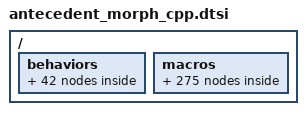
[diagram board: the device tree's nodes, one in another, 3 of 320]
// Cpp schema version v2.9
// Automatically generated by Antecedent Morph Configurator

/ {
    behaviors {
        // Mod-Morphs
        // Base layer
        // NE
        amcppneagm: amcppneagm {
            compatible = "zmk,behavior-mod-morph";
            #binding-cells = <0>;
            bindings = <&amcppnea>, <&amcppneg>;
            mods = <(MOD_LGUI)>;
        };
        amcppnecagm: amcppnecagm {
            compatible = "zmk,behavior-mod-morph";
            #binding-cells = <0>;
            bindings = <&amcppnec>, <&amcppneagm>;
            mods = <(MOD_LALT|MOD_LGUI)>;
        };
        amcppnem: amcppnem {
            compatible = "zmk,behavior-mod-morph";
            #binding-cells = <0>;
            bindings = <&amcppne>, <&amcppnecagm>;
            mods = <(MOD_LCTL|MOD_LALT|MOD_LGUI)>;
        };
        // E
        amcppeagm: amcppeagm {
            compatible = "zmk,behavior-mod-morph";
            #binding-cells = <0>;
            bindings = <&amcppea>, <&amcppeg>;
            mods = <(MOD_LGUI)>;
        };
        amcppecagm: amcppecagm {
            compatible = "zmk,behavior-mod-morph";
            #binding-cells = <0>;
            bindings = <&amcppec>, <&amcppeagm>;
            mods = <(MOD_LALT|MOD_LGUI)>;
        };
        amcppem: amcppem {
            compatible = "zmk,behavior-mod-morph";
            #binding-cells = <0>;
            bindings = <&amcppe>, <&amcppecagm>;
            mods = <(MOD_LCTL|MOD_LALT|MOD_LGUI)>;
        };
        // SE
        amcppseagm: amcppseagm {
            compatible = "zmk,behavior-mod-morph";
            #binding-cells = <0>;
            bindings = <&amcppsea>, <&amcppseg>;
            mods = <(MOD_LGUI)>;
        };
        amcppsecagm: amcppsecagm {
            compatible = "zmk,behavior-mod-morph";
            #binding-cells = <0>;
            bindings = <&amcppsec>, <&amcppseagm>;
            mods = <(MOD_LALT|MOD_LGUI)>;
        };
        amcppsem: amcppsem {
            compatible = "zmk,behavior-mod-morph";
            #binding-cells = <0>;
            bindings = <&amcppse>, <&amcppsecagm>;
            mods = <(MOD_LCTL|MOD_LALT|MOD_LGUI)>;
        };
        // NW
        amcppnwagm: amcppnwagm {
            compatible = "zmk,behavior-mod-morph";
            #binding-cells = <0>;
            bindings = <&amcppnwa>, <&amcppnwg>;
            mods = <(MOD_RGUI)>;
        };
        amcppnwcagm: amcppnwcagm {
            compatible = "zmk,behavior-mod-morph";
            #binding-cells = <0>;
            bindings = <&amcppnwc>, <&amcppnwagm>;
            mods = <(MOD_RALT|MOD_RGUI)>;
        };
        amcppnwm: amcppnwm {
            compatible = "zmk,behavior-mod-morph";
            #binding-cells = <0>;
            bindings = <&amcppnw>, <&amcppnwcagm>;
            mods = <(MOD_RCTL|MOD_RALT|MOD_RGUI)>;
        };
        // W
        amcppwagm: amcppwagm {
            compatible = "zmk,behavior-mod-morph";
            #binding-cells = <0>;
            bindings = <&amcppwa>, <&amcppwg>;
            mods = <(MOD_RGUI)>;
        };
        amcppwcagm: amcppwcagm {
            compatible = "zmk,behavior-mod-morph";
            #binding-cells = <0>;
            bindings = <&amcppwc>, <&amcppwagm>;
            mods = <(MOD_RALT|MOD_RGUI)>;
        };
        amcppwm: amcppwm {
            compatible = "zmk,behavior-mod-morph";
            #binding-cells = <0>;
            bindings = <&amcppw>, <&amcppwcagm>;
            mods = <(MOD_RCTL|MOD_RALT|MOD_RGUI)>;
        };
        // SW
        amcppswagm: amcppswagm {
            compatible = "zmk,behavior-mod-morph";
            #binding-cells = <0>;
            bindings = <&amcppswa>, <&amcppswg>;
            mods = <(MOD_RGUI)>;
        };
        amcppswcagm: amcppswcagm {
            compatible = "zmk,behavior-mod-morph";
            #binding-cells = <0>;
            bindings = <&amcppswc>, <&amcppswagm>;
            mods = <(MOD_RALT|MOD_RGUI)>;
        };
        amcppswm: amcppswm {
            compatible = "zmk,behavior-mod-morph";
            #binding-cells = <0>;
            bindings = <&amcppsw>, <&amcppswcagm>;
            mods = <(MOD_RCTL|MOD_RALT|MOD_RGUI)>;
        };
        // Antecedent Morphs
        amcppne: am_cpp_ne {
            compatible = "zmk,behavior-antecedent-morph";
            label = "AM_CPP_NE";
            #binding-cells = <0>;
            defaults = <&none>;
            bindings = <&amcpp_assert>, <&amcpp_break>, <&amcpp_case>, <&amcpp_default>, <&amcpp_enum>, <&amcpp_for>, <&amcpp_int_main>, <&amcpp_long_double>, <&amcpp_module>, <&amcpp_null>, <&amcpp_operator>, <&amcpp_private>, <&amcpp_qobject>, <&amcpp_return>, <&amcpp_struct>, <&amcpp_template>, <&amcpp_union>, <&amcpp_stdvector>, <&amcpp_while>, <&amcpp_extern>, <&amcpp_1024>, <&amcpp_4096>, <&amcpp_m3>, <&amcpp_m6>, <&amcpp_m10>, <&amcpp_void2>, <&amcpp_m16>, <&kp EQUAL>, <&amcpp_qt>, <&kp EQUAL>, <&kp EQUAL>, <&kp EQUAL>, <&kp EQUAL>, <&amcpp_error>, <&kp EQUAL>, <&kp EQUAL>, <&amcpp_m20>, <&amcpp_m25>, <&amcpp_m30>, <&kp EQUAL>;
            antecedents = <A B C D E F I L M N O P Q R S T U V W X N1 N4 SQT LBRC RBRC LPAR RPAR STAR COLON PRCNT CARET PLUS EXCL HASH PIPE AMPS LBKT RBKT EQUAL MINUS>;
            max-delay-ms = <U_ANTMORPH_DELAY>;
        };
        amcppnec: am_cpp_ne_c {
            compatible = "zmk,behavior-antecedent-morph";
            label = "AM_CPP_NE_C";
            #binding-cells = <0>;
            defaults = <&none>;
            bindings = <&amcpp_break1>, <&amcpp_default1>, <&amcpp_int_mainint_arg>, <&amcpp_long_double1>, <&amcpp_private1>, <&amcpp_qobjectcast>, <&amcpp_return1>, <&amcpp_typename>, <&amcpp_int_argc_char_a>, <&amcpp_this1>, <&amcpp_m26>, <&amcpp_m31>;
            antecedents = <B D I L P Q R T LPAR LBKT RBKT EQUAL>;
            max-delay-ms = <U_ANTMORPH_DELAY>;
        };
        amcppnea: am_cpp_ne_a {
            compatible = "zmk,behavior-antecedent-morph";
            label = "AM_CPP_NE_A";
            #binding-cells = <0>;
            defaults = <&none>;
            bindings = <&amcpp_qflag>, <&amcpp_int_mainvoid>, <&amcpp_long_double_con>, <&amcpp_qobject1>, <&amcpp_m21>, <&amcpp_m32>;
            antecedents = <E I L Q LBKT EQUAL>;
            max-delay-ms = <U_ANTMORPH_DELAY>;
        };
        amcppneg: am_cpp_ne_g {
            compatible = "zmk,behavior-antecedent-morph";
            label = "AM_CPP_NE_G";
            #binding-cells = <0>;
            defaults = <&none>;
            bindings = <&amcpp_qassert>, <&amcpp_qenum>, <&amcpp_private_slots>, <&amcpp_qgadget>;
            antecedents = <A E P Q>;
            max-delay-ms = <U_ANTMORPH_DELAY>;
        };
        amcppe: am_cpp_e {
            compatible = "zmk,behavior-antecedent-morph";
            label = "AM_CPP_E";
            #binding-cells = <0>;
            defaults = <&none>;
            bindings = <&amcpp_auto>, <&amcpp_bool>, <&amcpp_const>, <&amcpp_double>, <&amcpp_emit>, <&amcpp_float>, <&amcpp_goto>, <&amcpp_short>, <&amcpp_inline>, <&amcpp_long>, <&amcpp_stdmakeunique>, <&amcpp_nullptr>, <&amcpp_public>, <&amcpp_qstring>, <&amcpp_return2>, <&amcpp_static>, <&amcpp_this>, <&amcpp_using>, <&amcpp_void>, <&amcpp_qwidget>, <&amcpp_explicit>, <&amcpp_stdpair>, <&amcpp_stdtuple>, <&amcpp_stdcout>, <&amcpp_stdcin>, <&kp SEMI>, <&amcpp_m7>, <&kp SEMI>, <&amcpp_m13>, <&kp SEMI>, <&amcpp_void3>, <&amcpp_std>, <&amcpp_05>, <&amcpp_pragma>, <&amcpp_l11>, <&amcpp_m22>, <&kp SEMI>, <&amcpp_m28>, <&amcpp_01>, <&amcpp_rn>, <&kp GT>, <&amcpp_cpp_v29>;
            antecedents = <A B C D E F G H I L M N P Q R S T U V W X N2 N3 COMMA DOT SQT LBRC RBRC LPAR RPAR STAR COLON PLUS HASH UNDER LBKT RBKT SEMI EQUAL BSLH MINUS SPACE>;
            max-delay-ms = <U_ANTMORPH_DELAY>;
        };
        amcppec: am_cpp_e_c {
            compatible = "zmk,behavior-antecedent-morph";
            label = "AM_CPP_E_C";
            #binding-cells = <0>;
            defaults = <&none>;
            bindings = <&amcpp_auto_const>, <&amcpp_const1>, <&amcpp_double1>, <&amcpp_long1>, <&amcpp_public1>, <&amcpp_qstringview>, <&amcpp_staticcast>, <&amcpp_this_>, <&amcpp_void1>, <&amcpp_m4>, <&amcpp_m8>, <&amcpp_m11>, <&amcpp_m14>, <&amcpp_m17>, <&amcpp_void_const1>, <&amcpp_pragma_once>, <&amcpp_m23>, <&amcpp_m27>, <&amcpp_00>;
            antecedents = <A C D L P Q S T V SQT LBRC RBRC LPAR RPAR STAR HASH LBKT RBKT EQUAL>;
            max-delay-ms = <U_ANTMORPH_DELAY>;
        };
        amcppea: am_cpp_e_a {
            compatible = "zmk,behavior-antecedent-morph";
            label = "AM_CPP_E_A";
            #binding-cells = <0>;
            defaults = <&none>;
            bindings = <&amcpp_auto_const1>, <&amcpp_const2>, <&amcpp_double_const>, <&amcpp_long_const>, <&amcpp_qchar>, <&amcpp_void_const>, <&amcpp_l1>;
            antecedents = <A C D L Q V SQT>;
            max-delay-ms = <U_ANTMORPH_DELAY>;
        };
        amcppeg: am_cpp_e_g {
            compatible = "zmk,behavior-antecedent-morph";
            label = "AM_CPP_E_G";
            #binding-cells = <0>;
            defaults = <&none>;
            bindings = <&amcpp_auto1>, <&amcpp_constcast>, <&amcpp_public_slots>, <&amcpp_signals>, <&amcpp_ba>;
            antecedents = <A C P S SQT>;
            max-delay-ms = <U_ANTMORPH_DELAY>;
        };
        amcppse: am_cpp_se {
            compatible = "zmk,behavior-antecedent-morph";
            label = "AM_CPP_SE";
            #binding-cells = <0>;
            defaults = <&none>;
            bindings = <&amcpp_staticassert>, <&amcpp_begin>, <&amcpp_class>, <&amcpp_define>, <&amcpp_exit>, <&amcpp_final>, <&amcpp_import>, <&amcpp_mutable>, <&amcpp_0>, <&amcpp_protected>, <&amcpp_qvariant>, <&amcpp_register>, <&amcpp_signed>, <&amcpp_throw>, <&amcpp_unsigned>, <&amcpp_virtual>, <&amcpp_export>, <&amcpp_m>, <&amcpp_m5>, <&amcpp_m9>, <&amcpp_m12>, <&amcpp_m15>, <&amcpp_m18>, <&amcpp_char2>, <&amcpp_boost>, <&amcpp_warning>, <&amcpp_m24>, <&amcpp_m29>, <&amcpp_m33>, <&amcpp_rnrn>;
            antecedents = <A B C D E F I M N P Q R S T U V X COMMA SQT LBRC RBRC LPAR RPAR STAR COLON HASH LBKT SEMI EQUAL BSLH>;
            max-delay-ms = <U_ANTMORPH_DELAY>;
        };
        amcppsec: am_cpp_se_c {
            compatible = "zmk,behavior-antecedent-morph";
            label = "AM_CPP_SE_C";
            #binding-cells = <0>;
            defaults = <&none>;
            bindings = <&amcpp_cbegin>, <&amcpp_protected1>, <&amcpp_qvariantcast>, <&amcpp_try>, <&amcpp_m1>, <&amcpp_char_const1>, <&amcpp_deprecated>, <&amcpp_02>;
            antecedents = <B P Q T COMMA STAR LBKT EQUAL>;
            max-delay-ms = <U_ANTMORPH_DELAY>;
        };
        amcppsea: am_cpp_se_a {
            compatible = "zmk,behavior-antecedent-morph";
            label = "AM_CPP_SE_A";
            #binding-cells = <0>;
            defaults = <&none>;
            bindings = <&amcpp_rbegin>, <&amcpp_deprecated1>;
            antecedents = <B LBKT>;
            max-delay-ms = <U_ANTMORPH_DELAY>;
        };
        amcppseg: am_cpp_se_g {
            compatible = "zmk,behavior-antecedent-morph";
            label = "AM_CPP_SE_G";
            #binding-cells = <0>;
            defaults = <&none>;
            bindings = <&amcpp_crbegin>, <&amcpp_protected_slots>;
            antecedents = <B P>;
            max-delay-ms = <U_ANTMORPH_DELAY>;
        };
        amcppnw: am_cpp_nw {
            compatible = "zmk,behavior-antecedent-morph";
            label = "AM_CPP_NW";
            #binding-cells = <0>;
            defaults = <&none>;
            bindings = <&amcpp_asm>, <&amcpp_connect>, <&amcpp_delete>, <&amcpp_else_if>, <&amcpp_friend>, <&amcpp_char>, <&amcpp_int>, <&amcpp_stdmove>, <&amcpp_namespace>, <&amcpp_override>, <&amcpp_puts>, <&amcpp_qdebug>, <&amcpp_restrict>, <&amcpp_switch>, <&amcpp_typedef>, <&amcpp_stduniqueptr>, <&amcpp_volatile>, <&kp EQUAL>, <&kp EQUAL>, <&amcpp_include>, <&kp EQUAL>, <&amcpp_m19>, <&amcpp_embed>, <&amcpp_thread>, <&amcpp_expects>;
            antecedents = <A C D E F H I M N O P Q R S T U V COMMA DOT SQT FSLH RPAR HASH UNDER LBKT>;
            max-delay-ms = <U_ANTMORPH_DELAY>;
        };
        amcppnwc: am_cpp_nw_c {
            compatible = "zmk,behavior-antecedent-morph";
            label = "AM_CPP_NW_C";
            #binding-cells = <0>;
            defaults = <&none>;
            bindings = <&amcpp_asm_volatile__m>, <&amcpp_qobjectconnect>, <&amcpp_delete1>, <&amcpp_elif>, <&amcpp_char1>, <&amcpp_int1>, <&amcpp_namespace1>, <&amcpp_qcdebug>, <&amcpp_include_h>;
            antecedents = <A C D E H I N Q SQT>;
            max-delay-ms = <U_ANTMORPH_DELAY>;
        };
        amcppnwa: am_cpp_nw_a {
            compatible = "zmk,behavior-antecedent-morph";
            label = "AM_CPP_NW_A";
            #binding-cells = <0>;
            defaults = <&none>;
            bindings = <&amcpp_asm_volatilemfe>, <&amcpp_char_const>, <&amcpp_int_const>, <&amcpp_include_hpp>;
            antecedents = <A H I SQT>;
            max-delay-ms = <U_ANTMORPH_DELAY>;
        };
        amcppnwg: am_cpp_nw_g {
            compatible = "zmk,behavior-antecedent-morph";
            label = "AM_CPP_NW_G";
            #binding-cells = <0>;
            defaults = <&none>;
            bindings = <&none>;
            antecedents = <0x070100>;
            max-delay-ms = <U_ANTMORPH_DELAY>;
        };
        amcppw: am_cpp_w {
            compatible = "zmk,behavior-antecedent-morph";
            label = "AM_CPP_W";
            #binding-cells = <0>;
            defaults = <&none>;
            bindings = <&amcpp_stdasconst>, <&amcpp_continue>, <&amcpp_defined>, <&amcpp_else>, <&amcpp_free>, <&amcpp_catch>, <&amcpp_if>, <&amcpp_lse>, <&amcpp_malloc>, <&amcpp_false>, <&amcpp_stdoptional>, <&amcpp_printf>, <&amcpp_qsizetype>, <&amcpp_realloc>, <&amcpp_sizeof>, <&amcpp_sizet>, <&amcpp_using_namespace>, <&amcpp_vprintf>, <&amcpp_stdexchange>, <&amcpp_true>, <&amcpp_m2>, <&amcpp_endif>, <&amcpp_include1>, <&amcpp_ifdef>, <&amcpp_defined1>, <&amcpp_attribute>, <&amcpp_fallthrough>, <&amcpp_undef>;
            antecedents = <A C D E F H I L M N O P Q R S T U V X Y COMMA DOT SQT FSLH EXCL UNDER LBKT SPACE>;
            max-delay-ms = <U_ANTMORPH_DELAY>;
        };
        amcppwc: am_cpp_w_c {
            compatible = "zmk,behavior-antecedent-morph";
            label = "AM_CPP_W_C";
            #binding-cells = <0>;
            defaults = <&none>;
            bindings = <&amcpp_continue1>, <&amcpp_else1>, <&amcpp_catch1>, <&amcpp_if1>, <&amcpp_fprintf>, <&amcpp_sizeof1>, <&amcpp_ptrdifft>, <&amcpp_vfprintf>, <&amcpp_include_h1>, <&amcpp_ifndef>, <&amcpp_attribute_visib>, <&amcpp_likely>;
            antecedents = <C E H I P S T V SQT FSLH UNDER LBKT>;
            max-delay-ms = <U_ANTMORPH_DELAY>;
        };
        amcppwa: am_cpp_w_a {
            compatible = "zmk,behavior-antecedent-morph";
            label = "AM_CPP_W_A";
            #binding-cells = <0>;
            defaults = <&none>;
            bindings = <&amcpp_if_constexpr>, <&amcpp_sprintf>, <&amcpp_vsprintf>, <&amcpp_attribute_visib1>, <&amcpp_unlikely>;
            antecedents = <I P V UNDER LBKT>;
            max-delay-ms = <U_ANTMORPH_DELAY>;
        };
        amcppwg: am_cpp_w_g {
            compatible = "zmk,behavior-antecedent-morph";
            label = "AM_CPP_W_G";
            #binding-cells = <0>;
            defaults = <&none>;
            bindings = <&amcpp_snprintf>, <&amcpp_vsnprintf>, <&amcpp_attribute_secti>;
            antecedents = <P V UNDER>;
            max-delay-ms = <U_ANTMORPH_DELAY>;
        };
        amcppsw: am_cpp_sw {
            compatible = "zmk,behavior-antecedent-morph";
            label = "AM_CPP_SW";
            #binding-cells = <0>;
            defaults = <&none>;
            bindings = <&amcpp_alignas>, <&amcpp_constexpr>, <&amcpp_do>, <&amcpp_end>, <&amcpp_int64t>, <&amcpp_new>, <&amcpp_qbytearray>, <&amcpp_stdin>, <&amcpp_threadlocal>, <&amcpp_uint64t>, <&amcpp_elifdef>, <&amcpp_declspec>, <&amcpp_maybeunused>;
            antecedents = <A C D E I N Q S T U FSLH UNDER LBKT>;
            max-delay-ms = <U_ANTMORPH_DELAY>;
        };
        amcppswc: am_cpp_sw_c {
            compatible = "zmk,behavior-antecedent-morph";
            label = "AM_CPP_SW_C";
            #binding-cells = <0>;
            defaults = <&none>;
            bindings = <&amcpp_alignof>, <&amcpp_cend>, <&amcpp_int32t>, <&amcpp_stdout>, <&amcpp_uint32t>, <&amcpp_elifndef>, <&amcpp_nodiscard>;
            antecedents = <A E I S U FSLH LBKT>;
            max-delay-ms = <U_ANTMORPH_DELAY>;
        };
        amcppswa: am_cpp_sw_a {
            compatible = "zmk,behavior-antecedent-morph";
            label = "AM_CPP_SW_A";
            #binding-cells = <0>;
            defaults = <&none>;
            bindings = <&amcpp_rend>, <&amcpp_int16t>, <&amcpp_stderr>, <&amcpp_uint16t>, <&amcpp_nodiscard1>;
            antecedents = <E I S U LBKT>;
            max-delay-ms = <U_ANTMORPH_DELAY>;
        };
        amcppswg: am_cpp_sw_g {
            compatible = "zmk,behavior-antecedent-morph";
            label = "AM_CPP_SW_G";
            #binding-cells = <0>;
            defaults = <&none>;
            bindings = <&amcpp_crend>, <&amcpp_int8t>, <&amcpp_uint8t>;
            antecedents = <E I U>;
            max-delay-ms = <U_ANTMORPH_DELAY>;
        };
    };
    macros {
        // 'A'
        amcpp_assert: amcpp_assert {
            compatible = "zmk,behavior-macro";
            #binding-cells = <0>;
            wait-ms = <U_ANTMORPH_MACRO_WAIT>;
            tap-ms = <U_ANTMORPH_MACRO_TAP>;
            // (a)ssert(
            bindings = <&macro_tap &kp S &kp S &kp E &kp R &kp T &kp LPAR>;
        };
        amcpp_qassert: amcpp_qassert {
            compatible = "zmk,behavior-macro";
            #binding-cells = <0>;
            wait-ms = <U_ANTMORPH_MACRO_WAIT>;
            tap-ms = <U_ANTMORPH_MACRO_TAP>;
            // [a]Q_ASSERT(
            bindings = <&macro_release &kp LGUI>, <&macro_tap &kp LGUI>, <&macro_tap &kp BSPC &kp LS(Q) &kp UNDER &kp LS(A) &kp LS(S) &kp LS(S) &kp LS(E) &kp LS(R) &kp LS(T) &kp LPAR>;
        };
        amcpp_auto: amcpp_auto {
            compatible = "zmk,behavior-macro";
            #binding-cells = <0>;
            wait-ms = <U_ANTMORPH_MACRO_WAIT>;
            tap-ms = <U_ANTMORPH_MACRO_TAP>;
            // (a)uto
            bindings = <&macro_tap &kp U &kp T &kp O>;
        };
        amcpp_auto_const: amcpp_auto_const {
            compatible = "zmk,behavior-macro";
            #binding-cells = <0>;
            wait-ms = <U_ANTMORPH_MACRO_WAIT>;
            tap-ms = <U_ANTMORPH_MACRO_TAP>;
            // (a)uto const &
            bindings = <&macro_release &kp LCTRL>, <&macro_tap &kp U &kp T &kp O &kp SPACE &kp C &kp O &kp N &kp S &kp T &kp SPACE &kp AMPS>;
        };
        amcpp_auto_const1: amcpp_auto_const1 {
            compatible = "zmk,behavior-macro";
            #binding-cells = <0>;
            wait-ms = <U_ANTMORPH_MACRO_WAIT>;
            tap-ms = <U_ANTMORPH_MACRO_TAP>;
            // (a)uto const
            bindings = <&macro_release &kp LALT>, <&macro_tap &kp LALT>, <&macro_tap &kp U &kp T &kp O &kp SPACE &kp C &kp O &kp N &kp S &kp T>;
        };
        amcpp_auto1: amcpp_auto1 {
            compatible = "zmk,behavior-macro";
            #binding-cells = <0>;
            wait-ms = <U_ANTMORPH_MACRO_WAIT>;
            tap-ms = <U_ANTMORPH_MACRO_TAP>;
            // (a)uto *
            bindings = <&macro_release &kp LGUI>, <&macro_tap &kp LGUI>, <&macro_tap &kp U &kp T &kp O &kp SPACE &kp STAR>;
        };
        amcpp_staticassert: amcpp_staticassert {
            compatible = "zmk,behavior-macro";
            #binding-cells = <0>;
            wait-ms = <U_ANTMORPH_MACRO_WAIT>;
            tap-ms = <U_ANTMORPH_MACRO_TAP>;
            // [a]static_assert(
            bindings = <&macro_tap &kp BSPC &kp S &kp T &kp A &kp T &kp I &kp C &kp UNDER &kp A &kp S &kp S &kp E &kp R &kp T &kp LPAR>;
        };
        amcpp_asm: amcpp_asm {
            compatible = "zmk,behavior-macro";
            #binding-cells = <0>;
            wait-ms = <U_ANTMORPH_MACRO_WAIT>;
            tap-ms = <U_ANTMORPH_MACRO_TAP>;
            // (a)sm ("
            bindings = <&macro_tap &kp S &kp M &kp SPACE &kp LPAR &kp DQT>;
        };
        amcpp_asm_volatile__m: amcpp_asm_volatile__m {
            compatible = "zmk,behavior-macro";
            #binding-cells = <0>;
            wait-ms = <U_ANTMORPH_MACRO_WAIT>;
            tap-ms = <U_ANTMORPH_MACRO_TAP>;
            // (a)sm volatile(""  ::: "memory")
            bindings = <&macro_release &kp RCTRL>, <&macro_tap &kp S &kp M &kp SPACE &kp V &kp O &kp L &kp A &kp T &kp I &kp L &kp E &kp LPAR &kp DQT &kp DQT &kp SPACE &kp SPACE &kp COLON &kp COLON &kp COLON &kp SPACE &kp DQT &kp M &kp E &kp M &kp O &kp R &kp Y &kp DQT &kp RPAR>;
        };
        amcpp_asm_volatilemfe: amcpp_asm_volatilemfe {
            compatible = "zmk,behavior-macro";
            #binding-cells = <0>;
            wait-ms = <U_ANTMORPH_MACRO_WAIT>;
            tap-ms = <U_ANTMORPH_MACRO_TAP>;
            // (a)sm volatile("mfence" :: "memory")
            bindings = <&macro_release &kp RALT>, <&macro_tap &kp RALT>, <&macro_tap &kp S &kp M &kp SPACE &kp V &kp O &kp L &kp A &kp T &kp I &kp L &kp E &kp LPAR &kp DQT &kp M &kp F &kp E &kp N &kp C &kp E &kp DQT &kp SPACE &kp COLON &kp COLON &kp SPACE &kp DQT &kp M &kp E &kp M &kp O &kp R &kp Y &kp DQT &kp RPAR>;
        };
        amcpp_stdasconst: amcpp_stdasconst {
            compatible = "zmk,behavior-macro";
            #binding-cells = <0>;
            wait-ms = <U_ANTMORPH_MACRO_WAIT>;
            tap-ms = <U_ANTMORPH_MACRO_TAP>;
            // [a]std::as_const(
            bindings = <&macro_tap &kp BSPC &kp S &kp T &kp D &kp COLON &kp COLON &kp A &kp S &kp UNDER &kp C &kp O &kp N &kp S &kp T &kp LPAR>;
        };
        amcpp_alignas: amcpp_alignas {
            compatible = "zmk,behavior-macro";
            #binding-cells = <0>;
            wait-ms = <U_ANTMORPH_MACRO_WAIT>;
            tap-ms = <U_ANTMORPH_MACRO_TAP>;
            // (a)lignas(
            bindings = <&macro_tap &kp L &kp I &kp G &kp N &kp A &kp S &kp LPAR>;
        };
        amcpp_alignof: amcpp_alignof {
            compatible = "zmk,behavior-macro";
            #binding-cells = <0>;
            wait-ms = <U_ANTMORPH_MACRO_WAIT>;
            tap-ms = <U_ANTMORPH_MACRO_TAP>;
            // (a)lignof(
            bindings = <&macro_release &kp RCTRL>, <&macro_tap &kp L &kp I &kp G &kp N &kp O &kp F &kp LPAR>;
        };
        // 'B'
        amcpp_break: amcpp_break {
            compatible = "zmk,behavior-macro";
            #binding-cells = <0>;
            wait-ms = <U_ANTMORPH_MACRO_WAIT>;
            tap-ms = <U_ANTMORPH_MACRO_TAP>;
            // (b)reak;
            bindings = <&macro_tap &kp R &kp E &kp A &kp K &kp SEMI>;
        };
        amcpp_break1: amcpp_break1 {
            compatible = "zmk,behavior-macro";
            #binding-cells = <0>;
            wait-ms = <U_ANTMORPH_MACRO_WAIT>;
            tap-ms = <U_ANTMORPH_MACRO_TAP>;
            // (b)reak;⏎
            bindings = <&macro_release &kp LCTRL>, <&macro_tap &kp R &kp E &kp A &kp K &kp SEMI &kp RET>;
        };
        amcpp_bool: amcpp_bool {
            compatible = "zmk,behavior-macro";
            #binding-cells = <0>;
            wait-ms = <U_ANTMORPH_MACRO_WAIT>;
            tap-ms = <U_ANTMORPH_MACRO_TAP>;
            // (b)ool
            bindings = <&macro_tap &kp O &kp O &kp L>;
        };
        amcpp_begin: amcpp_begin {
            compatible = "zmk,behavior-macro";
            #binding-cells = <0>;
            wait-ms = <U_ANTMORPH_MACRO_WAIT>;
            tap-ms = <U_ANTMORPH_MACRO_TAP>;
            // (b)egin()
            bindings = <&macro_tap &kp E &kp G &kp I &kp N &kp LPAR &kp RPAR>;
        };
        amcpp_cbegin: amcpp_cbegin {
            compatible = "zmk,behavior-macro";
            #binding-cells = <0>;
            wait-ms = <U_ANTMORPH_MACRO_WAIT>;
            tap-ms = <U_ANTMORPH_MACRO_TAP>;
            // [b]cbegin()
            bindings = <&macro_release &kp LCTRL>, <&macro_tap &kp BSPC &kp C &kp B &kp E &kp G &kp I &kp N &kp LPAR &kp RPAR>;
        };
        amcpp_rbegin: amcpp_rbegin {
            compatible = "zmk,behavior-macro";
            #binding-cells = <0>;
            wait-ms = <U_ANTMORPH_MACRO_WAIT>;
            tap-ms = <U_ANTMORPH_MACRO_TAP>;
            // [b]rbegin()
            bindings = <&macro_release &kp LALT>, <&macro_tap &kp LALT>, <&macro_tap &kp BSPC &kp R &kp B &kp E &kp G &kp I &kp N &kp LPAR &kp RPAR>;
        };
        amcpp_crbegin: amcpp_crbegin {
            compatible = "zmk,behavior-macro";
            #binding-cells = <0>;
            wait-ms = <U_ANTMORPH_MACRO_WAIT>;
            tap-ms = <U_ANTMORPH_MACRO_TAP>;
            // [b]crbegin()
            bindings = <&macro_release &kp LGUI>, <&macro_tap &kp LGUI>, <&macro_tap &kp BSPC &kp C &kp R &kp B &kp E &kp G &kp I &kp N &kp LPAR &kp RPAR>;
        };
        // 'C'
        amcpp_case: amcpp_case {
            compatible = "zmk,behavior-macro";
            #binding-cells = <0>;
            wait-ms = <U_ANTMORPH_MACRO_WAIT>;
            tap-ms = <U_ANTMORPH_MACRO_TAP>;
            // (c)ase 
            bindings = <&macro_tap &kp A &kp S &kp E &kp SPACE>;
        };
        amcpp_const: amcpp_const {
            compatible = "zmk,behavior-macro";
            #binding-cells = <0>;
            wait-ms = <U_ANTMORPH_MACRO_WAIT>;
            tap-ms = <U_ANTMORPH_MACRO_TAP>;
            // (c)onst
            bindings = <&macro_tap &kp O &kp N &kp S &kp T>;
        };
        amcpp_const1: amcpp_const1 {
            compatible = "zmk,behavior-macro";
            #binding-cells = <0>;
            wait-ms = <U_ANTMORPH_MACRO_WAIT>;
            tap-ms = <U_ANTMORPH_MACRO_TAP>;
            // (c)onst *
            bindings = <&macro_release &kp LCTRL>, <&macro_tap &kp O &kp N &kp S &kp T &kp SPACE &kp STAR>;
        };
        amcpp_const2: amcpp_const2 {
            compatible = "zmk,behavior-macro";
            #binding-cells = <0>;
            wait-ms = <U_ANTMORPH_MACRO_WAIT>;
            tap-ms = <U_ANTMORPH_MACRO_TAP>;
            // (c)onst &
            bindings = <&macro_release &kp LALT>, <&macro_tap &kp LALT>, <&macro_tap &kp O &kp N &kp S &kp T &kp SPACE &kp AMPS>;
        };
        amcpp_constcast: amcpp_constcast {
            compatible = "zmk,behavior-macro";
            #binding-cells = <0>;
            wait-ms = <U_ANTMORPH_MACRO_WAIT>;
            tap-ms = <U_ANTMORPH_MACRO_TAP>;
            // (c)onst_cast<
            bindings = <&macro_release &kp LGUI>, <&macro_tap &kp LGUI>, <&macro_tap &kp O &kp N &kp S &kp T &kp UNDER &kp C &kp A &kp S &kp T &kp LT>;
        };
        amcpp_class: amcpp_class {
            compatible = "zmk,behavior-macro";
            #binding-cells = <0>;
            wait-ms = <U_ANTMORPH_MACRO_WAIT>;
            tap-ms = <U_ANTMORPH_MACRO_TAP>;
            // (c)lass 
            bindings = <&macro_tap &kp L &kp A &kp S &kp S &kp SPACE>;
        };
        amcpp_connect: amcpp_connect {
            compatible = "zmk,behavior-macro";
            #binding-cells = <0>;
            wait-ms = <U_ANTMORPH_MACRO_WAIT>;
            tap-ms = <U_ANTMORPH_MACRO_TAP>;
            // (c)onnect(
            bindings = <&macro_tap &kp O &kp N &kp N &kp E &kp C &kp T &kp LPAR>;
        };
        amcpp_qobjectconnect: amcpp_qobjectconnect {
            compatible = "zmk,behavior-macro";
            #binding-cells = <0>;
            wait-ms = <U_ANTMORPH_MACRO_WAIT>;
            tap-ms = <U_ANTMORPH_MACRO_TAP>;
            // [c]QObject::connect(
            bindings = <&macro_release &kp RCTRL>, <&macro_tap &kp BSPC &kp LS(Q) &kp LS(O) &kp B &kp J &kp E &kp C &kp T &kp COLON &kp COLON &kp C &kp O &kp N &kp N &kp E &kp C &kp T &kp LPAR>;
        };
        amcpp_continue: amcpp_continue {
            compatible = "zmk,behavior-macro";
            #binding-cells = <0>;
            wait-ms = <U_ANTMORPH_MACRO_WAIT>;
            tap-ms = <U_ANTMORPH_MACRO_TAP>;
            // (c)ontinue;
            bindings = <&macro_tap &kp O &kp N &kp T &kp I &kp N &kp U &kp E &kp SEMI>;
        };
        amcpp_continue1: amcpp_continue1 {
            compatible = "zmk,behavior-macro";
            #binding-cells = <0>;
            wait-ms = <U_ANTMORPH_MACRO_WAIT>;
            tap-ms = <U_ANTMORPH_MACRO_TAP>;
            // (c)ontinue;⏎
            bindings = <&macro_release &kp RCTRL>, <&macro_tap &kp O &kp N &kp T &kp I &kp N &kp U &kp E &kp SEMI &kp RET>;
        };
        amcpp_constexpr: amcpp_constexpr {
            compatible = "zmk,behavior-macro";
            #binding-cells = <0>;
            wait-ms = <U_ANTMORPH_MACRO_WAIT>;
            tap-ms = <U_ANTMORPH_MACRO_TAP>;
            // (c)onstexpr
            bindings = <&macro_tap &kp O &kp N &kp S &kp T &kp E &kp X &kp P &kp R>;
        };
        // 'D'
        amcpp_default: amcpp_default {
            compatible = "zmk,behavior-macro";
            #binding-cells = <0>;
            wait-ms = <U_ANTMORPH_MACRO_WAIT>;
            tap-ms = <U_ANTMORPH_MACRO_TAP>;
            // (d)efault
            bindings = <&macro_tap &kp E &kp F &kp A &kp U &kp L &kp T>;
        };
        amcpp_default1: amcpp_default1 {
            compatible = "zmk,behavior-macro";
            #binding-cells = <0>;
            wait-ms = <U_ANTMORPH_MACRO_WAIT>;
            tap-ms = <U_ANTMORPH_MACRO_TAP>;
            // (d)efault:⏎
            bindings = <&macro_release &kp LCTRL>, <&macro_tap &kp E &kp F &kp A &kp U &kp L &kp T &kp COLON &kp RET>;
        };
        amcpp_double: amcpp_double {
            compatible = "zmk,behavior-macro";
            #binding-cells = <0>;
            wait-ms = <U_ANTMORPH_MACRO_WAIT>;
            tap-ms = <U_ANTMORPH_MACRO_TAP>;
            // (d)ouble
            bindings = <&macro_tap &kp O &kp U &kp B &kp L &kp E>;
        };
        amcpp_double1: amcpp_double1 {
            compatible = "zmk,behavior-macro";
            #binding-cells = <0>;
            wait-ms = <U_ANTMORPH_MACRO_WAIT>;
            tap-ms = <U_ANTMORPH_MACRO_TAP>;
            // (d)ouble *
            bindings = <&macro_release &kp LCTRL>, <&macro_tap &kp O &kp U &kp B &kp L &kp E &kp SPACE &kp STAR>;
        };
        amcpp_double_const: amcpp_double_const {
            compatible = "zmk,behavior-macro";
            #binding-cells = <0>;
            wait-ms = <U_ANTMORPH_MACRO_WAIT>;
            tap-ms = <U_ANTMORPH_MACRO_TAP>;
            // (d)ouble const *
            bindings = <&macro_release &kp LALT>, <&macro_tap &kp LALT>, <&macro_tap &kp O &kp U &kp B &kp L &kp E &kp SPACE &kp C &kp O &kp N &kp S &kp T &kp SPACE &kp STAR>;
        };
        amcpp_define: amcpp_define {
            compatible = "zmk,behavior-macro";
            #binding-cells = <0>;
            wait-ms = <U_ANTMORPH_MACRO_WAIT>;
            tap-ms = <U_ANTMORPH_MACRO_TAP>;
            // [d]#define 
            bindings = <&macro_tap &kp BSPC &kp HASH &kp D &kp E &kp F &kp I &kp N &kp E &kp SPACE>;
        };
        amcpp_delete: amcpp_delete {
            compatible = "zmk,behavior-macro";
            #binding-cells = <0>;
            wait-ms = <U_ANTMORPH_MACRO_WAIT>;
            tap-ms = <U_ANTMORPH_MACRO_TAP>;
            // (d)elete
            bindings = <&macro_tap &kp E &kp L &kp E &kp T &kp E>;
        };
        amcpp_delete1: amcpp_delete1 {
            compatible = "zmk,behavior-macro";
            #binding-cells = <0>;
            wait-ms = <U_ANTMORPH_MACRO_WAIT>;
            tap-ms = <U_ANTMORPH_MACRO_TAP>;
            // (d)elete[] 
            bindings = <&macro_release &kp RCTRL>, <&macro_tap &kp E &kp L &kp E &kp T &kp E &kp LBKT &kp RBKT &kp SPACE>;
        };
        amcpp_defined: amcpp_defined {
            compatible = "zmk,behavior-macro";
            #binding-cells = <0>;
            wait-ms = <U_ANTMORPH_MACRO_WAIT>;
            tap-ms = <U_ANTMORPH_MACRO_TAP>;
            // (d)efined(
            bindings = <&macro_tap &kp E &kp F &kp I &kp N &kp E &kp D &kp LPAR>;
        };
        amcpp_do: amcpp_do {
            compatible = "zmk,behavior-macro";
            #binding-cells = <0>;
            wait-ms = <U_ANTMORPH_MACRO_WAIT>;
            tap-ms = <U_ANTMORPH_MACRO_TAP>;
            // (d)o {⏎
            bindings = <&macro_tap &kp O &kp SPACE &kp LBRC &kp RET>;
        };
        // 'E'
        amcpp_enum: amcpp_enum {
            compatible = "zmk,behavior-macro";
            #binding-cells = <0>;
            wait-ms = <U_ANTMORPH_MACRO_WAIT>;
            tap-ms = <U_ANTMORPH_MACRO_TAP>;
            // (e)num 
            bindings = <&macro_tap &kp N &kp U &kp M &kp SPACE>;
        };
        amcpp_qflag: amcpp_qflag {
            compatible = "zmk,behavior-macro";
            #binding-cells = <0>;
            wait-ms = <U_ANTMORPH_MACRO_WAIT>;
            tap-ms = <U_ANTMORPH_MACRO_TAP>;
            // [e]Q_FLAG(
            bindings = <&macro_release &kp LALT>, <&macro_tap &kp LALT>, <&macro_tap &kp BSPC &kp LS(Q) &kp UNDER &kp LS(F) &kp LS(L) &kp LS(A) &kp LS(G) &kp LPAR>;
        };
        amcpp_qenum: amcpp_qenum {
            compatible = "zmk,behavior-macro";
            #binding-cells = <0>;
            wait-ms = <U_ANTMORPH_MACRO_WAIT>;
            tap-ms = <U_ANTMORPH_MACRO_TAP>;
            // [e]Q_ENUM(
            bindings = <&macro_release &kp LGUI>, <&macro_tap &kp LGUI>, <&macro_tap &kp BSPC &kp LS(Q) &kp UNDER &kp LS(E) &kp LS(N) &kp LS(U) &kp LS(M) &kp LPAR>;
        };
        amcpp_emit: amcpp_emit {
            compatible = "zmk,behavior-macro";
            #binding-cells = <0>;
            wait-ms = <U_ANTMORPH_MACRO_WAIT>;
            tap-ms = <U_ANTMORPH_MACRO_TAP>;
            // (e)mit 
            bindings = <&macro_tap &kp M &kp I &kp T &kp SPACE>;
        };
        amcpp_exit: amcpp_exit {
            compatible = "zmk,behavior-macro";
            #binding-cells = <0>;
            wait-ms = <U_ANTMORPH_MACRO_WAIT>;
            tap-ms = <U_ANTMORPH_MACRO_TAP>;
            // (e)xit(
            bindings = <&macro_tap &kp X &kp I &kp T &kp LPAR>;
        };
        amcpp_else_if: amcpp_else_if {
            compatible = "zmk,behavior-macro";
            #binding-cells = <0>;
            wait-ms = <U_ANTMORPH_MACRO_WAIT>;
            tap-ms = <U_ANTMORPH_MACRO_TAP>;
            // (e)lse if (
            bindings = <&macro_tap &kp L &kp S &kp E &kp SPACE &kp I &kp F &kp SPACE &kp LPAR>;
        };
        amcpp_elif: amcpp_elif {
            compatible = "zmk,behavior-macro";
            #binding-cells = <0>;
            wait-ms = <U_ANTMORPH_MACRO_WAIT>;
            tap-ms = <U_ANTMORPH_MACRO_TAP>;
            // [e]#elif 
            bindings = <&macro_release &kp RCTRL>, <&macro_tap &kp BSPC &kp HASH &kp E &kp L &kp I &kp F &kp SPACE>;
        };
        amcpp_else: amcpp_else {
            compatible = "zmk,behavior-macro";
            #binding-cells = <0>;
            wait-ms = <U_ANTMORPH_MACRO_WAIT>;
            tap-ms = <U_ANTMORPH_MACRO_TAP>;
            // (e)lse
            bindings = <&macro_tap &kp L &kp S &kp E>;
        };
        amcpp_else1: amcpp_else1 {
            compatible = "zmk,behavior-macro";
            #binding-cells = <0>;
            wait-ms = <U_ANTMORPH_MACRO_WAIT>;
            tap-ms = <U_ANTMORPH_MACRO_TAP>;
            // [e]#else
            bindings = <&macro_release &kp RCTRL>, <&macro_tap &kp BSPC &kp HASH &kp E &kp L &kp S &kp E>;
        };
        amcpp_end: amcpp_end {
            compatible = "zmk,behavior-macro";
            #binding-cells = <0>;
            wait-ms = <U_ANTMORPH_MACRO_WAIT>;
            tap-ms = <U_ANTMORPH_MACRO_TAP>;
            // (e)nd()
            bindings = <&macro_tap &kp N &kp D &kp LPAR &kp RPAR>;
        };
        amcpp_cend: amcpp_cend {
            compatible = "zmk,behavior-macro";
            #binding-cells = <0>;
            wait-ms = <U_ANTMORPH_MACRO_WAIT>;
            tap-ms = <U_ANTMORPH_MACRO_TAP>;
            // [e]cend()
            bindings = <&macro_release &kp RCTRL>, <&macro_tap &kp BSPC &kp C &kp E &kp N &kp D &kp LPAR &kp RPAR>;
        };
        amcpp_rend: amcpp_rend {
            compatible = "zmk,behavior-macro";
            #binding-cells = <0>;
            wait-ms = <U_ANTMORPH_MACRO_WAIT>;
            tap-ms = <U_ANTMORPH_MACRO_TAP>;
            // [e]rend()
            bindings = <&macro_release &kp RALT>, <&macro_tap &kp RALT>, <&macro_tap &kp BSPC &kp R &kp E &kp N &kp D &kp LPAR &kp RPAR>;
        };
        amcpp_crend: amcpp_crend {
            compatible = "zmk,behavior-macro";
            #binding-cells = <0>;
            wait-ms = <U_ANTMORPH_MACRO_WAIT>;
            tap-ms = <U_ANTMORPH_MACRO_TAP>;
            // [e]crend()
            bindings = <&macro_release &kp RGUI>, <&macro_tap &kp RGUI>, <&macro_tap &kp BSPC &kp C &kp R &kp E &kp N &kp D &kp LPAR &kp RPAR>;
        };
        // 'F'
        amcpp_for: amcpp_for {
            compatible = "zmk,behavior-macro";
            #binding-cells = <0>;
            wait-ms = <U_ANTMORPH_MACRO_WAIT>;
            tap-ms = <U_ANTMORPH_MACRO_TAP>;
            // (f)or (
            bindings = <&macro_tap &kp O &kp R &kp SPACE &kp LPAR>;
        };
        amcpp_float: amcpp_float {
            compatible = "zmk,behavior-macro";
            #binding-cells = <0>;
            wait-ms = <U_ANTMORPH_MACRO_WAIT>;
            tap-ms = <U_ANTMORPH_MACRO_TAP>;
            // (f)loat
            bindings = <&macro_tap &kp L &kp O &kp A &kp T>;
        };
        amcpp_final: amcpp_final {
            compatible = "zmk,behavior-macro";
            #binding-cells = <0>;
            wait-ms = <U_ANTMORPH_MACRO_WAIT>;
            tap-ms = <U_ANTMORPH_MACRO_TAP>;
            // (f)inal
            bindings = <&macro_tap &kp I &kp N &kp A &kp L>;
        };
        amcpp_friend: amcpp_friend {
            compatible = "zmk,behavior-macro";
            #binding-cells = <0>;
            wait-ms = <U_ANTMORPH_MACRO_WAIT>;
            tap-ms = <U_ANTMORPH_MACRO_TAP>;
            // (f)riend 
            bindings = <&macro_tap &kp R &kp I &kp E &kp N &kp D &kp SPACE>;
        };
        amcpp_free: amcpp_free {
            compatible = "zmk,behavior-macro";
            #binding-cells = <0>;
            wait-ms = <U_ANTMORPH_MACRO_WAIT>;
            tap-ms = <U_ANTMORPH_MACRO_TAP>;
            // (f)ree(
            bindings = <&macro_tap &kp R &kp E &kp E &kp LPAR>;
        };
        // 'G'
        amcpp_goto: amcpp_goto {
            compatible = "zmk,behavior-macro";
            #binding-cells = <0>;
            wait-ms = <U_ANTMORPH_MACRO_WAIT>;
            tap-ms = <U_ANTMORPH_MACRO_TAP>;
            // (g)oto 
            bindings = <&macro_tap &kp O &kp T &kp O &kp SPACE>;
        };
        // 'H'
        amcpp_short: amcpp_short {
            compatible = "zmk,behavior-macro";
            #binding-cells = <0>;
            wait-ms = <U_ANTMORPH_MACRO_WAIT>;
            tap-ms = <U_ANTMORPH_MACRO_TAP>;
            // [h]short
            bindings = <&macro_tap &kp BSPC &kp S &kp H &kp O &kp R &kp T>;
        };
        amcpp_char: amcpp_char {
            compatible = "zmk,behavior-macro";
            #binding-cells = <0>;
            wait-ms = <U_ANTMORPH_MACRO_WAIT>;
            tap-ms = <U_ANTMORPH_MACRO_TAP>;
            // [h]char
            bindings = <&macro_tap &kp BSPC &kp C &kp H &kp A &kp R>;
        };
        amcpp_char1: amcpp_char1 {
            compatible = "zmk,behavior-macro";
            #binding-cells = <0>;
            wait-ms = <U_ANTMORPH_MACRO_WAIT>;
            tap-ms = <U_ANTMORPH_MACRO_TAP>;
            // [h]char *
            bindings = <&macro_release &kp RCTRL>, <&macro_tap &kp BSPC &kp C &kp H &kp A &kp R &kp SPACE &kp STAR>;
        };
        amcpp_char_const: amcpp_char_const {
            compatible = "zmk,behavior-macro";
            #binding-cells = <0>;
            wait-ms = <U_ANTMORPH_MACRO_WAIT>;
            tap-ms = <U_ANTMORPH_MACRO_TAP>;
            // [h]char const *
            bindings = <&macro_release &kp RALT>, <&macro_tap &kp RALT>, <&macro_tap &kp BSPC &kp C &kp H &kp A &kp R &kp SPACE &kp C &kp O &kp N &kp S &kp T &kp SPACE &kp STAR>;
        };
        amcpp_catch: amcpp_catch {
            compatible = "zmk,behavior-macro";
            #binding-cells = <0>;
            wait-ms = <U_ANTMORPH_MACRO_WAIT>;
            tap-ms = <U_ANTMORPH_MACRO_TAP>;
            // [h]catch (
            bindings = <&macro_tap &kp BSPC &kp C &kp A &kp T &kp C &kp H &kp SPACE &kp LPAR>;
        };
        amcpp_catch1: amcpp_catch1 {
            compatible = "zmk,behavior-macro";
            #binding-cells = <0>;
            wait-ms = <U_ANTMORPH_MACRO_WAIT>;
            tap-ms = <U_ANTMORPH_MACRO_TAP>;
            // [h]catch (...) {⏎
            bindings = <&macro_release &kp RCTRL>, <&macro_tap &kp BSPC &kp C &kp A &kp T &kp C &kp H &kp SPACE &kp LPAR &kp DOT &kp DOT &kp DOT &kp RPAR &kp SPACE &kp LBRC &kp RET>;
        };
        // 'I'
        amcpp_int_main: amcpp_int_main {
            compatible = "zmk,behavior-macro";
            #binding-cells = <0>;
            wait-ms = <U_ANTMORPH_MACRO_WAIT>;
            tap-ms = <U_ANTMORPH_MACRO_TAP>;
            // (i)nt main()⏎{⏎
            bindings = <&macro_tap &kp N &kp T &kp SPACE &kp M &kp A &kp I &kp N &kp LPAR &kp RPAR &kp RET &kp LBRC &kp RET>;
        };
        amcpp_int_mainint_arg: amcpp_int_mainint_arg {
            compatible = "zmk,behavior-macro";
            #binding-cells = <0>;
            wait-ms = <U_ANTMORPH_MACRO_WAIT>;
            tap-ms = <U_ANTMORPH_MACRO_TAP>;
            // (i)nt main(int argc, char **argv)⏎{⏎
            bindings = <&macro_release &kp LCTRL>, <&macro_tap &kp N &kp T &kp SPACE &kp M &kp A &kp I &kp N &kp LPAR &kp I &kp N &kp T &kp SPACE &kp A &kp R &kp G &kp C &kp COMMA &kp SPACE &kp C &kp H &kp A &kp R &kp SPACE &kp STAR &kp STAR &kp A &kp R &kp G &kp V &kp RPAR &kp RET &kp LBRC &kp RET>;
        };
        amcpp_int_mainvoid: amcpp_int_mainvoid {
            compatible = "zmk,behavior-macro";
            #binding-cells = <0>;
            wait-ms = <U_ANTMORPH_MACRO_WAIT>;
            tap-ms = <U_ANTMORPH_MACRO_TAP>;
            // (i)nt main(void)⏎{⏎
            bindings = <&macro_release &kp LALT>, <&macro_tap &kp LALT>, <&macro_tap &kp N &kp T &kp SPACE &kp M &kp A &kp I &kp N &kp LPAR &kp V &kp O &kp I &kp D &kp RPAR &kp RET &kp LBRC &kp RET>;
        };
        amcpp_inline: amcpp_inline {
            compatible = "zmk,behavior-macro";
            #binding-cells = <0>;
            wait-ms = <U_ANTMORPH_MACRO_WAIT>;
            tap-ms = <U_ANTMORPH_MACRO_TAP>;
            // (i)nline 
            bindings = <&macro_tap &kp N &kp L &kp I &kp N &kp E &kp SPACE>;
        };
        amcpp_import: amcpp_import {
            compatible = "zmk,behavior-macro";
            #binding-cells = <0>;
            wait-ms = <U_ANTMORPH_MACRO_WAIT>;
            tap-ms = <U_ANTMORPH_MACRO_TAP>;
            // (i)mport 
            bindings = <&macro_tap &kp M &kp P &kp O &kp R &kp T &kp SPACE>;
        };
        amcpp_int: amcpp_int {
            compatible = "zmk,behavior-macro";
            #binding-cells = <0>;
            wait-ms = <U_ANTMORPH_MACRO_WAIT>;
            tap-ms = <U_ANTMORPH_MACRO_TAP>;
            // (i)nt
            bindings = <&macro_tap &kp N &kp T>;
        };
        amcpp_int1: amcpp_int1 {
            compatible = "zmk,behavior-macro";
            #binding-cells = <0>;
            wait-ms = <U_ANTMORPH_MACRO_WAIT>;
            tap-ms = <U_ANTMORPH_MACRO_TAP>;
            // (i)nt *
            bindings = <&macro_release &kp RCTRL>, <&macro_tap &kp N &kp T &kp SPACE &kp STAR>;
        };
        amcpp_int_const: amcpp_int_const {
            compatible = "zmk,behavior-macro";
            #binding-cells = <0>;
            wait-ms = <U_ANTMORPH_MACRO_WAIT>;
            tap-ms = <U_ANTMORPH_MACRO_TAP>;
            // (i)nt const *
            bindings = <&macro_release &kp RALT>, <&macro_tap &kp RALT>, <&macro_tap &kp N &kp T &kp SPACE &kp C &kp O &kp N &kp S &kp T &kp SPACE &kp STAR>;
        };
        amcpp_if: amcpp_if {
            compatible = "zmk,behavior-macro";
            #binding-cells = <0>;
            wait-ms = <U_ANTMORPH_MACRO_WAIT>;
            tap-ms = <U_ANTMORPH_MACRO_TAP>;
            // (i)f (
            bindings = <&macro_tap &kp F &kp SPACE &kp LPAR>;
        };
        amcpp_if1: amcpp_if1 {
            compatible = "zmk,behavior-macro";
            #binding-cells = <0>;
            wait-ms = <U_ANTMORPH_MACRO_WAIT>;
            tap-ms = <U_ANTMORPH_MACRO_TAP>;
            // [i]#if 
            bindings = <&macro_release &kp RCTRL>, <&macro_tap &kp BSPC &kp HASH &kp I &kp F &kp SPACE>;
        };
        amcpp_if_constexpr: amcpp_if_constexpr {
            compatible = "zmk,behavior-macro";
            #binding-cells = <0>;
            wait-ms = <U_ANTMORPH_MACRO_WAIT>;
            tap-ms = <U_ANTMORPH_MACRO_TAP>;
            // (i)f constexpr (
            bindings = <&macro_release &kp RALT>, <&macro_tap &kp RALT>, <&macro_tap &kp F &kp SPACE &kp C &kp O &kp N &kp S &kp T &kp E &kp X &kp P &kp R &kp SPACE &kp LPAR>;
        };
        amcpp_int64t: amcpp_int64t {
            compatible = "zmk,behavior-macro";
            #binding-cells = <0>;
            wait-ms = <U_ANTMORPH_MACRO_WAIT>;
            tap-ms = <U_ANTMORPH_MACRO_TAP>;
            // (i)nt64_t
            bindings = <&macro_tap &kp N &kp T &kp N6 &kp N4 &kp UNDER &kp T>;
        };
        amcpp_int32t: amcpp_int32t {
            compatible = "zmk,behavior-macro";
            #binding-cells = <0>;
            wait-ms = <U_ANTMORPH_MACRO_WAIT>;
            tap-ms = <U_ANTMORPH_MACRO_TAP>;
            // (i)nt32_t
            bindings = <&macro_release &kp RCTRL>, <&macro_tap &kp N &kp T &kp N3 &kp N2 &kp UNDER &kp T>;
        };
        amcpp_int16t: amcpp_int16t {
            compatible = "zmk,behavior-macro";
            #binding-cells = <0>;
            wait-ms = <U_ANTMORPH_MACRO_WAIT>;
            tap-ms = <U_ANTMORPH_MACRO_TAP>;
            // (i)nt16_t
            bindings = <&macro_release &kp RALT>, <&macro_tap &kp RALT>, <&macro_tap &kp N &kp T &kp N1 &kp N6 &kp UNDER &kp T>;
        };
        amcpp_int8t: amcpp_int8t {
            compatible = "zmk,behavior-macro";
            #binding-cells = <0>;
            wait-ms = <U_ANTMORPH_MACRO_WAIT>;
            tap-ms = <U_ANTMORPH_MACRO_TAP>;
            // (i)nt8_t
            bindings = <&macro_release &kp RGUI>, <&macro_tap &kp RGUI>, <&macro_tap &kp N &kp T &kp N8 &kp UNDER &kp T>;
        };
        // 'L'
        amcpp_long_double: amcpp_long_double {
            compatible = "zmk,behavior-macro";
            #binding-cells = <0>;
            wait-ms = <U_ANTMORPH_MACRO_WAIT>;
            tap-ms = <U_ANTMORPH_MACRO_TAP>;
            // (l)ong double
            bindings = <&macro_tap &kp O &kp N &kp G &kp SPACE &kp D &kp O &kp U &kp B &kp L &kp E>;
        };
        amcpp_long_double1: amcpp_long_double1 {
            compatible = "zmk,behavior-macro";
            #binding-cells = <0>;
            wait-ms = <U_ANTMORPH_MACRO_WAIT>;
            tap-ms = <U_ANTMORPH_MACRO_TAP>;
            // (l)ong double *
            bindings = <&macro_release &kp LCTRL>, <&macro_tap &kp O &kp N &kp G &kp SPACE &kp D &kp O &kp U &kp B &kp L &kp E &kp SPACE &kp STAR>;
        };
        amcpp_long_double_con: amcpp_long_double_con {
            compatible = "zmk,behavior-macro";
            #binding-cells = <0>;
            wait-ms = <U_ANTMORPH_MACRO_WAIT>;
            tap-ms = <U_ANTMORPH_MACRO_TAP>;
            // (l)ong double const *
            bindings = <&macro_release &kp LALT>, <&macro_tap &kp LALT>, <&macro_tap &kp O &kp N &kp G &kp SPACE &kp D &kp O &kp U &kp B &kp L &kp E &kp SPACE &kp C &kp O &kp N &kp S &kp T &kp SPACE &kp STAR>;
        };
        amcpp_long: amcpp_long {
            compatible = "zmk,behavior-macro";
            #binding-cells = <0>;
            wait-ms = <U_ANTMORPH_MACRO_WAIT>;
            tap-ms = <U_ANTMORPH_MACRO_TAP>;
            // (l)ong
            bindings = <&macro_tap &kp O &kp N &kp G>;
        };
        amcpp_long1: amcpp_long1 {
            compatible = "zmk,behavior-macro";
            #binding-cells = <0>;
            wait-ms = <U_ANTMORPH_MACRO_WAIT>;
            tap-ms = <U_ANTMORPH_MACRO_TAP>;
            // (l)ong *
            bindings = <&macro_release &kp LCTRL>, <&macro_tap &kp O &kp N &kp G &kp SPACE &kp STAR>;
        };
        amcpp_long_const: amcpp_long_const {
            compatible = "zmk,behavior-macro";
            #binding-cells = <0>;
            wait-ms = <U_ANTMORPH_MACRO_WAIT>;
            tap-ms = <U_ANTMORPH_MACRO_TAP>;
            // (l)ong const *
            bindings = <&macro_release &kp LALT>, <&macro_tap &kp LALT>, <&macro_tap &kp O &kp N &kp G &kp SPACE &kp C &kp O &kp N &kp S &kp T &kp SPACE &kp STAR>;
        };
        amcpp_lse: amcpp_lse {
            compatible = "zmk,behavior-macro";
            #binding-cells = <0>;
            wait-ms = <U_ANTMORPH_MACRO_WAIT>;
            tap-ms = <U_ANTMORPH_MACRO_TAP>;
            // (l)se {⏎
            bindings = <&macro_tap &kp S &kp E &kp SPACE &kp LBRC &kp RET>;
        };
        // 'M'
        amcpp_module: amcpp_module {
            compatible = "zmk,behavior-macro";
            #binding-cells = <0>;
            wait-ms = <U_ANTMORPH_MACRO_WAIT>;
            tap-ms = <U_ANTMORPH_MACRO_TAP>;
            // (m)odule
            bindings = <&macro_tap &kp O &kp D &kp U &kp L &kp E>;
        };
        amcpp_stdmakeunique: amcpp_stdmakeunique {
            compatible = "zmk,behavior-macro";
            #binding-cells = <0>;
            wait-ms = <U_ANTMORPH_MACRO_WAIT>;
            tap-ms = <U_ANTMORPH_MACRO_TAP>;
            // [m]std::make_unique<
            bindings = <&macro_tap &kp BSPC &kp S &kp T &kp D &kp COLON &kp COLON &kp M &kp A &kp K &kp E &kp UNDER &kp U &kp N &kp I &kp Q &kp U &kp E &kp LT>;
        };
        amcpp_mutable: amcpp_mutable {
            compatible = "zmk,behavior-macro";
            #binding-cells = <0>;
            wait-ms = <U_ANTMORPH_MACRO_WAIT>;
            tap-ms = <U_ANTMORPH_MACRO_TAP>;
            // (m)utable 
            bindings = <&macro_tap &kp U &kp T &kp A &kp B &kp L &kp E &kp SPACE>;
        };
        amcpp_stdmove: amcpp_stdmove {
            compatible = "zmk,behavior-macro";
            #binding-cells = <0>;
            wait-ms = <U_ANTMORPH_MACRO_WAIT>;
            tap-ms = <U_ANTMORPH_MACRO_TAP>;
            // [m]std::move(
            bindings = <&macro_tap &kp BSPC &kp S &kp T &kp D &kp COLON &kp COLON &kp M &kp O &kp V &kp E &kp LPAR>;
        };
        amcpp_malloc: amcpp_malloc {
            compatible = "zmk,behavior-macro";
            #binding-cells = <0>;
            wait-ms = <U_ANTMORPH_MACRO_WAIT>;
            tap-ms = <U_ANTMORPH_MACRO_TAP>;
            // (m)alloc(
            bindings = <&macro_tap &kp A &kp L &kp L &kp O &kp C &kp LPAR>;
        };
        // 'N'
        amcpp_null: amcpp_null {
            compatible = "zmk,behavior-macro";
            #binding-cells = <0>;
            wait-ms = <U_ANTMORPH_MACRO_WAIT>;
            tap-ms = <U_ANTMORPH_MACRO_TAP>;
            // (n)ULL
            bindings = <&macro_tap &kp LS(U) &kp LS(L) &kp LS(L)>;
        };
        amcpp_nullptr: amcpp_nullptr {
            compatible = "zmk,behavior-macro";
            #binding-cells = <0>;
            wait-ms = <U_ANTMORPH_MACRO_WAIT>;
            tap-ms = <U_ANTMORPH_MACRO_TAP>;
            // (n)ullptr
            bindings = <&macro_tap &kp U &kp L &kp L &kp P &kp T &kp R>;
        };
        amcpp_0: amcpp_0 {
            compatible = "zmk,behavior-macro";
            #binding-cells = <0>;
            wait-ms = <U_ANTMORPH_MACRO_WAIT>;
            tap-ms = <U_ANTMORPH_MACRO_TAP>;
            // [n]\0
            bindings = <&macro_tap &kp BSPC &kp BSLH &kp N0>;
        };
        amcpp_namespace: amcpp_namespace {
            compatible = "zmk,behavior-macro";
            #binding-cells = <0>;
            wait-ms = <U_ANTMORPH_MACRO_WAIT>;
            tap-ms = <U_ANTMORPH_MACRO_TAP>;
            // (n)amespace 
            bindings = <&macro_tap &kp A &kp M &kp E &kp S &kp P &kp A &kp C &kp E &kp SPACE>;
        };
        amcpp_namespace1: amcpp_namespace1 {
            compatible = "zmk,behavior-macro";
            #binding-cells = <0>;
            wait-ms = <U_ANTMORPH_MACRO_WAIT>;
            tap-ms = <U_ANTMORPH_MACRO_TAP>;
            // (n)amespace {⏎
            bindings = <&macro_release &kp RCTRL>, <&macro_tap &kp A &kp M &kp E &kp S &kp P &kp A &kp C &kp E &kp SPACE &kp LBRC &kp RET>;
        };
        amcpp_false: amcpp_false {
            compatible = "zmk,behavior-macro";
            #binding-cells = <0>;
            wait-ms = <U_ANTMORPH_MACRO_WAIT>;
            tap-ms = <U_ANTMORPH_MACRO_TAP>;
            // [n]false
            bindings = <&macro_tap &kp BSPC &kp F &kp A &kp L &kp S &kp E>;
        };
        amcpp_new: amcpp_new {
            compatible = "zmk,behavior-macro";
            #binding-cells = <0>;
            wait-ms = <U_ANTMORPH_MACRO_WAIT>;
            tap-ms = <U_ANTMORPH_MACRO_TAP>;
            // (n)ew 
            bindings = <&macro_tap &kp E &kp W &kp SPACE>;
        };
        // 'O'
        amcpp_operator: amcpp_operator {
            compatible = "zmk,behavior-macro";
            #binding-cells = <0>;
            wait-ms = <U_ANTMORPH_MACRO_WAIT>;
            tap-ms = <U_ANTMORPH_MACRO_TAP>;
            // (o)perator
            bindings = <&macro_tap &kp P &kp E &kp R &kp A &kp T &kp O &kp R>;
        };
        amcpp_override: amcpp_override {
            compatible = "zmk,behavior-macro";
            #binding-cells = <0>;
            wait-ms = <U_ANTMORPH_MACRO_WAIT>;
            tap-ms = <U_ANTMORPH_MACRO_TAP>;
            // (o)verride
            bindings = <&macro_tap &kp V &kp E &kp R &kp R &kp I &kp D &kp E>;
        };
        amcpp_stdoptional: amcpp_stdoptional {
            compatible = "zmk,behavior-macro";
            #binding-cells = <0>;
            wait-ms = <U_ANTMORPH_MACRO_WAIT>;
            tap-ms = <U_ANTMORPH_MACRO_TAP>;
            // [o]std::optional<
            bindings = <&macro_tap &kp BSPC &kp S &kp T &kp D &kp COLON &kp COLON &kp O &kp P &kp T &kp I &kp O &kp N &kp A &kp L &kp LT>;
        };
        // 'P'
        amcpp_private: amcpp_private {
            compatible = "zmk,behavior-macro";
            #binding-cells = <0>;
            wait-ms = <U_ANTMORPH_MACRO_WAIT>;
            tap-ms = <U_ANTMORPH_MACRO_TAP>;
            // (p)rivate
            bindings = <&macro_tap &kp R &kp I &kp V &kp A &kp T &kp E>;
        };
        amcpp_private1: amcpp_private1 {
            compatible = "zmk,behavior-macro";
            #binding-cells = <0>;
            wait-ms = <U_ANTMORPH_MACRO_WAIT>;
            tap-ms = <U_ANTMORPH_MACRO_TAP>;
            // (p)rivate:⏎
            bindings = <&macro_release &kp LCTRL>, <&macro_tap &kp R &kp I &kp V &kp A &kp T &kp E &kp COLON &kp RET>;
        };
        amcpp_private_slots: amcpp_private_slots {
            compatible = "zmk,behavior-macro";
            #binding-cells = <0>;
            wait-ms = <U_ANTMORPH_MACRO_WAIT>;
            tap-ms = <U_ANTMORPH_MACRO_TAP>;
            // (p)rivate slots:⏎
            bindings = <&macro_release &kp LGUI>, <&macro_tap &kp LGUI>, <&macro_tap &kp R &kp I &kp V &kp A &kp T &kp E &kp SPACE &kp S &kp L &kp O &kp T &kp S &kp COLON &kp RET>;
        };
        amcpp_public: amcpp_public {
            compatible = "zmk,behavior-macro";
            #binding-cells = <0>;
            wait-ms = <U_ANTMORPH_MACRO_WAIT>;
            tap-ms = <U_ANTMORPH_MACRO_TAP>;
            // (p)ublic
            bindings = <&macro_tap &kp U &kp B &kp L &kp I &kp C>;
        };
        amcpp_public1: amcpp_public1 {
            compatible = "zmk,behavior-macro";
            #binding-cells = <0>;
            wait-ms = <U_ANTMORPH_MACRO_WAIT>;
            tap-ms = <U_ANTMORPH_MACRO_TAP>;
            // (p)ublic:⏎
            bindings = <&macro_release &kp LCTRL>, <&macro_tap &kp U &kp B &kp L &kp I &kp C &kp COLON &kp RET>;
        };
        amcpp_public_slots: amcpp_public_slots {
            compatible = "zmk,behavior-macro";
            #binding-cells = <0>;
            wait-ms = <U_ANTMORPH_MACRO_WAIT>;
            tap-ms = <U_ANTMORPH_MACRO_TAP>;
            // (p)ublic slots:⏎
            bindings = <&macro_release &kp LGUI>, <&macro_tap &kp LGUI>, <&macro_tap &kp U &kp B &kp L &kp I &kp C &kp SPACE &kp S &kp L &kp O &kp T &kp S &kp COLON &kp RET>;
        };
        amcpp_protected: amcpp_protected {
            compatible = "zmk,behavior-macro";
            #binding-cells = <0>;
            wait-ms = <U_ANTMORPH_MACRO_WAIT>;
            tap-ms = <U_ANTMORPH_MACRO_TAP>;
            // (p)rotected
            bindings = <&macro_tap &kp R &kp O &kp T &kp E &kp C &kp T &kp E &kp D>;
        };
        amcpp_protected1: amcpp_protected1 {
            compatible = "zmk,behavior-macro";
            #binding-cells = <0>;
            wait-ms = <U_ANTMORPH_MACRO_WAIT>;
            tap-ms = <U_ANTMORPH_MACRO_TAP>;
            // (p)rotected:⏎
            bindings = <&macro_release &kp LCTRL>, <&macro_tap &kp R &kp O &kp T &kp E &kp C &kp T &kp E &kp D &kp COLON &kp RET>;
        };
        amcpp_protected_slots: amcpp_protected_slots {
            compatible = "zmk,behavior-macro";
            #binding-cells = <0>;
            wait-ms = <U_ANTMORPH_MACRO_WAIT>;
            tap-ms = <U_ANTMORPH_MACRO_TAP>;
            // (p)rotected slots:⏎
            bindings = <&macro_release &kp LGUI>, <&macro_tap &kp LGUI>, <&macro_tap &kp R &kp O &kp T &kp E &kp C &kp T &kp E &kp D &kp SPACE &kp S &kp L &kp O &kp T &kp S &kp COLON &kp RET>;
        };
        amcpp_puts: amcpp_puts {
            compatible = "zmk,behavior-macro";
            #binding-cells = <0>;
            wait-ms = <U_ANTMORPH_MACRO_WAIT>;
            tap-ms = <U_ANTMORPH_MACRO_TAP>;
            // (p)uts("
            bindings = <&macro_tap &kp U &kp T &kp S &kp LPAR &kp DQT>;
        };
        amcpp_printf: amcpp_printf {
            compatible = "zmk,behavior-macro";
            #binding-cells = <0>;
            wait-ms = <U_ANTMORPH_MACRO_WAIT>;
            tap-ms = <U_ANTMORPH_MACRO_TAP>;
            // (p)rintf("
            bindings = <&macro_tap &kp R &kp I &kp N &kp T &kp F &kp LPAR &kp DQT>;
        };
        amcpp_fprintf: amcpp_fprintf {
            compatible = "zmk,behavior-macro";
            #binding-cells = <0>;
            wait-ms = <U_ANTMORPH_MACRO_WAIT>;
            tap-ms = <U_ANTMORPH_MACRO_TAP>;
            // [p]fprintf(
            bindings = <&macro_release &kp RCTRL>, <&macro_tap &kp BSPC &kp F &kp P &kp R &kp I &kp N &kp T &kp F &kp LPAR>;
        };
        amcpp_sprintf: amcpp_sprintf {
            compatible = "zmk,behavior-macro";
            #binding-cells = <0>;
            wait-ms = <U_ANTMORPH_MACRO_WAIT>;
            tap-ms = <U_ANTMORPH_MACRO_TAP>;
            // [p]sprintf(
            bindings = <&macro_release &kp RALT>, <&macro_tap &kp RALT>, <&macro_tap &kp BSPC &kp S &kp P &kp R &kp I &kp N &kp T &kp F &kp LPAR>;
        };
        amcpp_snprintf: amcpp_snprintf {
            compatible = "zmk,behavior-macro";
            #binding-cells = <0>;
            wait-ms = <U_ANTMORPH_MACRO_WAIT>;
            tap-ms = <U_ANTMORPH_MACRO_TAP>;
            // [p]snprintf(
            bindings = <&macro_release &kp RGUI>, <&macro_tap &kp RGUI>, <&macro_tap &kp BSPC &kp S &kp N &kp P &kp R &kp I &kp N &kp T &kp F &kp LPAR>;
        };
        // 'Q'
        amcpp_qobject: amcpp_qobject {
            compatible = "zmk,behavior-macro";
            #binding-cells = <0>;
            wait-ms = <U_ANTMORPH_MACRO_WAIT>;
            tap-ms = <U_ANTMORPH_MACRO_TAP>;
            // (q)Object
            bindings = <&macro_tap &kp LS(O) &kp B &kp J &kp E &kp C &kp T>;
        };
        amcpp_qobjectcast: amcpp_qobjectcast {
            compatible = "zmk,behavior-macro";
            #binding-cells = <0>;
            wait-ms = <U_ANTMORPH_MACRO_WAIT>;
            tap-ms = <U_ANTMORPH_MACRO_TAP>;
            // (q)object_cast<
            bindings = <&macro_release &kp LCTRL>, <&macro_tap &kp O &kp B &kp J &kp E &kp C &kp T &kp UNDER &kp C &kp A &kp S &kp T &kp LT>;
        };
        amcpp_qobject1: amcpp_qobject1 {
            compatible = "zmk,behavior-macro";
            #binding-cells = <0>;
            wait-ms = <U_ANTMORPH_MACRO_WAIT>;
            tap-ms = <U_ANTMORPH_MACRO_TAP>;
            // (q)_OBJECT
            bindings = <&macro_release &kp LALT>, <&macro_tap &kp LALT>, <&macro_tap &kp UNDER &kp LS(O) &kp LS(B) &kp LS(J) &kp LS(E) &kp LS(C) &kp LS(T)>;
        };
        amcpp_qgadget: amcpp_qgadget {
            compatible = "zmk,behavior-macro";
            #binding-cells = <0>;
            wait-ms = <U_ANTMORPH_MACRO_WAIT>;
            tap-ms = <U_ANTMORPH_MACRO_TAP>;
            // (q)_GADGET
            bindings = <&macro_release &kp LGUI>, <&macro_tap &kp LGUI>, <&macro_tap &kp UNDER &kp LS(G) &kp LS(A) &kp LS(D) &kp LS(G) &kp LS(E) &kp LS(T)>;
        };
        amcpp_qstring: amcpp_qstring {
            compatible = "zmk,behavior-macro";
            #binding-cells = <0>;
            wait-ms = <U_ANTMORPH_MACRO_WAIT>;
            tap-ms = <U_ANTMORPH_MACRO_TAP>;
            // (q)String
            bindings = <&macro_tap &kp LS(S) &kp T &kp R &kp I &kp N &kp G>;
        };
        amcpp_qstringview: amcpp_qstringview {
            compatible = "zmk,behavior-macro";
            #binding-cells = <0>;
            wait-ms = <U_ANTMORPH_MACRO_WAIT>;
            tap-ms = <U_ANTMORPH_MACRO_TAP>;
            // (q)StringView
            bindings = <&macro_release &kp LCTRL>, <&macro_tap &kp LS(S) &kp T &kp R &kp I &kp N &kp G &kp LS(V) &kp I &kp E &kp W>;
        };
        amcpp_qchar: amcpp_qchar {
            compatible = "zmk,behavior-macro";
            #binding-cells = <0>;
            wait-ms = <U_ANTMORPH_MACRO_WAIT>;
            tap-ms = <U_ANTMORPH_MACRO_TAP>;
            // (q)Char
            bindings = <&macro_release &kp LALT>, <&macro_tap &kp LALT>, <&macro_tap &kp LS(C) &kp H &kp A &kp R>;
        };
        amcpp_qvariant: amcpp_qvariant {
            compatible = "zmk,behavior-macro";
            #binding-cells = <0>;
            wait-ms = <U_ANTMORPH_MACRO_WAIT>;
            tap-ms = <U_ANTMORPH_MACRO_TAP>;
            // (q)Variant
            bindings = <&macro_tap &kp LS(V) &kp A &kp R &kp I &kp A &kp N &kp T>;
        };
        amcpp_qvariantcast: amcpp_qvariantcast {
            compatible = "zmk,behavior-macro";
            #binding-cells = <0>;
            wait-ms = <U_ANTMORPH_MACRO_WAIT>;
            tap-ms = <U_ANTMORPH_MACRO_TAP>;
            // (q)variant_cast<
            bindings = <&macro_release &kp LCTRL>, <&macro_tap &kp V &kp A &kp R &kp I &kp A &kp N &kp T &kp UNDER &kp C &kp A &kp S &kp T &kp LT>;
        };
        amcpp_qdebug: amcpp_qdebug {
            compatible = "zmk,behavior-macro";
            #binding-cells = <0>;
            wait-ms = <U_ANTMORPH_MACRO_WAIT>;
            tap-ms = <U_ANTMORPH_MACRO_TAP>;
            // (q)Debug() << 
            bindings = <&macro_tap &kp LS(D) &kp E &kp B &kp U &kp G &kp LPAR &kp RPAR &kp SPACE &kp LT &kp LT &kp SPACE>;
        };
        amcpp_qcdebug: amcpp_qcdebug {
            compatible = "zmk,behavior-macro";
            #binding-cells = <0>;
            wait-ms = <U_ANTMORPH_MACRO_WAIT>;
            tap-ms = <U_ANTMORPH_MACRO_TAP>;
            // (q)CDebug(
            bindings = <&macro_release &kp RCTRL>, <&macro_tap &kp LS(C) &kp LS(D) &kp E &kp B &kp U &kp G &kp LPAR>;
        };
        amcpp_qsizetype: amcpp_qsizetype {
            compatible = "zmk,behavior-macro";
            #binding-cells = <0>;
            wait-ms = <U_ANTMORPH_MACRO_WAIT>;
            tap-ms = <U_ANTMORPH_MACRO_TAP>;
            // (q)sizetype
            bindings = <&macro_tap &kp S &kp I &kp Z &kp E &kp T &kp Y &kp P &kp E>;
        };
        amcpp_qbytearray: amcpp_qbytearray {
            compatible = "zmk,behavior-macro";
            #binding-cells = <0>;
            wait-ms = <U_ANTMORPH_MACRO_WAIT>;
            tap-ms = <U_ANTMORPH_MACRO_TAP>;
            // (q)ByteArray
            bindings = <&macro_tap &kp LS(B) &kp Y &kp T &kp E &kp LS(A) &kp R &kp R &kp A &kp Y>;
        };
        // 'R'
        amcpp_return: amcpp_return {
            compatible = "zmk,behavior-macro";
            #binding-cells = <0>;
            wait-ms = <U_ANTMORPH_MACRO_WAIT>;
            tap-ms = <U_ANTMORPH_MACRO_TAP>;
            // (r)eturn;
            bindings = <&macro_tap &kp E &kp T &kp U &kp R &kp N &kp SEMI>;
        };
        amcpp_return1: amcpp_return1 {
            compatible = "zmk,behavior-macro";
            #binding-cells = <0>;
            wait-ms = <U_ANTMORPH_MACRO_WAIT>;
            tap-ms = <U_ANTMORPH_MACRO_TAP>;
            // (r)eturn;⏎
            bindings = <&macro_release &kp LCTRL>, <&macro_tap &kp E &kp T &kp U &kp R &kp N &kp SEMI &kp RET>;
        };
        amcpp_return2: amcpp_return2 {
            compatible = "zmk,behavior-macro";
            #binding-cells = <0>;
            wait-ms = <U_ANTMORPH_MACRO_WAIT>;
            tap-ms = <U_ANTMORPH_MACRO_TAP>;
            // (r)eturn 
            bindings = <&macro_tap &kp E &kp T &kp U &kp R &kp N &kp SPACE>;
        };
        amcpp_register: amcpp_register {
            compatible = "zmk,behavior-macro";
            #binding-cells = <0>;
            wait-ms = <U_ANTMORPH_MACRO_WAIT>;
            tap-ms = <U_ANTMORPH_MACRO_TAP>;
            // (r)egister 
            bindings = <&macro_tap &kp E &kp G &kp I &kp S &kp T &kp E &kp R &kp SPACE>;
        };
        amcpp_restrict: amcpp_restrict {
            compatible = "zmk,behavior-macro";
            #binding-cells = <0>;
            wait-ms = <U_ANTMORPH_MACRO_WAIT>;
            tap-ms = <U_ANTMORPH_MACRO_TAP>;
            // (r)estrict 
            bindings = <&macro_tap &kp E &kp S &kp T &kp R &kp I &kp C &kp T &kp SPACE>;
        };
        amcpp_realloc: amcpp_realloc {
            compatible = "zmk,behavior-macro";
            #binding-cells = <0>;
            wait-ms = <U_ANTMORPH_MACRO_WAIT>;
            tap-ms = <U_ANTMORPH_MACRO_TAP>;
            // (r)ealloc(
            bindings = <&macro_tap &kp E &kp A &kp L &kp L &kp O &kp C &kp LPAR>;
        };
        // 'S'
        amcpp_struct: amcpp_struct {
            compatible = "zmk,behavior-macro";
            #binding-cells = <0>;
            wait-ms = <U_ANTMORPH_MACRO_WAIT>;
            tap-ms = <U_ANTMORPH_MACRO_TAP>;
            // (s)truct 
            bindings = <&macro_tap &kp T &kp R &kp U &kp C &kp T &kp SPACE>;
        };
        amcpp_static: amcpp_static {
            compatible = "zmk,behavior-macro";
            #binding-cells = <0>;
            wait-ms = <U_ANTMORPH_MACRO_WAIT>;
            tap-ms = <U_ANTMORPH_MACRO_TAP>;
            // (s)tatic 
            bindings = <&macro_tap &kp T &kp A &kp T &kp I &kp C &kp SPACE>;
        };
        amcpp_staticcast: amcpp_staticcast {
            compatible = "zmk,behavior-macro";
            #binding-cells = <0>;
            wait-ms = <U_ANTMORPH_MACRO_WAIT>;
            tap-ms = <U_ANTMORPH_MACRO_TAP>;
            // (s)tatic_cast<
            bindings = <&macro_release &kp LCTRL>, <&macro_tap &kp T &kp A &kp T &kp I &kp C &kp UNDER &kp C &kp A &kp S &kp T &kp LT>;
        };
        amcpp_signals: amcpp_signals {
            compatible = "zmk,behavior-macro";
            #binding-cells = <0>;
            wait-ms = <U_ANTMORPH_MACRO_WAIT>;
            tap-ms = <U_ANTMORPH_MACRO_TAP>;
            // (s)ignals:⏎
            bindings = <&macro_release &kp LGUI>, <&macro_tap &kp LGUI>, <&macro_tap &kp I &kp G &kp N &kp A &kp L &kp S &kp COLON &kp RET>;
        };
        amcpp_signed: amcpp_signed {
            compatible = "zmk,behavior-macro";
            #binding-cells = <0>;
            wait-ms = <U_ANTMORPH_MACRO_WAIT>;
            tap-ms = <U_ANTMORPH_MACRO_TAP>;
            // (s)igned
            bindings = <&macro_tap &kp I &kp G &kp N &kp E &kp D>;
        };
        amcpp_switch: amcpp_switch {
            compatible = "zmk,behavior-macro";
            #binding-cells = <0>;
            wait-ms = <U_ANTMORPH_MACRO_WAIT>;
            tap-ms = <U_ANTMORPH_MACRO_TAP>;
            // (s)witch (
            bindings = <&macro_tap &kp W &kp I &kp T &kp C &kp H &kp SPACE &kp LPAR>;
        };
        amcpp_sizeof: amcpp_sizeof {
            compatible = "zmk,behavior-macro";
            #binding-cells = <0>;
            wait-ms = <U_ANTMORPH_MACRO_WAIT>;
            tap-ms = <U_ANTMORPH_MACRO_TAP>;
            // (s)izeof
            bindings = <&macro_tap &kp I &kp Z &kp E &kp O &kp F>;
        };
        amcpp_sizeof1: amcpp_sizeof1 {
            compatible = "zmk,behavior-macro";
            #binding-cells = <0>;
            wait-ms = <U_ANTMORPH_MACRO_WAIT>;
            tap-ms = <U_ANTMORPH_MACRO_TAP>;
            // (s)izeof(
            bindings = <&macro_release &kp RCTRL>, <&macro_tap &kp I &kp Z &kp E &kp O &kp F &kp LPAR>;
        };
        amcpp_stdin: amcpp_stdin {
            compatible = "zmk,behavior-macro";
            #binding-cells = <0>;
            wait-ms = <U_ANTMORPH_MACRO_WAIT>;
            tap-ms = <U_ANTMORPH_MACRO_TAP>;
            // (s)tdin
            bindings = <&macro_tap &kp T &kp D &kp I &kp N>;
        };
        amcpp_stdout: amcpp_stdout {
            compatible = "zmk,behavior-macro";
            #binding-cells = <0>;
            wait-ms = <U_ANTMORPH_MACRO_WAIT>;
            tap-ms = <U_ANTMORPH_MACRO_TAP>;
            // (s)tdout
            bindings = <&macro_release &kp RCTRL>, <&macro_tap &kp T &kp D &kp O &kp U &kp T>;
        };
        amcpp_stderr: amcpp_stderr {
            compatible = "zmk,behavior-macro";
            #binding-cells = <0>;
            wait-ms = <U_ANTMORPH_MACRO_WAIT>;
            tap-ms = <U_ANTMORPH_MACRO_TAP>;
            // (s)tderr
            bindings = <&macro_release &kp RALT>, <&macro_tap &kp RALT>, <&macro_tap &kp T &kp D &kp E &kp R &kp R>;
        };
        // 'T'
        amcpp_template: amcpp_template {
            compatible = "zmk,behavior-macro";
            #binding-cells = <0>;
            wait-ms = <U_ANTMORPH_MACRO_WAIT>;
            tap-ms = <U_ANTMORPH_MACRO_TAP>;
            // (t)emplate
            bindings = <&macro_tap &kp E &kp M &kp P &kp L &kp A &kp T &kp E>;
        };
        amcpp_typename: amcpp_typename {
            compatible = "zmk,behavior-macro";
            #binding-cells = <0>;
            wait-ms = <U_ANTMORPH_MACRO_WAIT>;
            tap-ms = <U_ANTMORPH_MACRO_TAP>;
            // (t)ypename
            bindings = <&macro_release &kp LCTRL>, <&macro_tap &kp Y &kp P &kp E &kp N &kp A &kp M &kp E>;
        };
        amcpp_this: amcpp_this {
            compatible = "zmk,behavior-macro";
            #binding-cells = <0>;
            wait-ms = <U_ANTMORPH_MACRO_WAIT>;
            tap-ms = <U_ANTMORPH_MACRO_TAP>;
            // (t)his
            bindings = <&macro_tap &kp H &kp I &kp S>;
        };
        amcpp_this_: amcpp_this_ {
            compatible = "zmk,behavior-macro";
            #binding-cells = <0>;
            wait-ms = <U_ANTMORPH_MACRO_WAIT>;
            tap-ms = <U_ANTMORPH_MACRO_TAP>;
            // (t)his->
            bindings = <&macro_release &kp LCTRL>, <&macro_tap &kp H &kp I &kp S &kp MINUS &kp GT>;
        };
        amcpp_throw: amcpp_throw {
            compatible = "zmk,behavior-macro";
            #binding-cells = <0>;
            wait-ms = <U_ANTMORPH_MACRO_WAIT>;
            tap-ms = <U_ANTMORPH_MACRO_TAP>;
            // (t)hrow 
            bindings = <&macro_tap &kp H &kp R &kp O &kp W &kp SPACE>;
        };
        amcpp_try: amcpp_try {
            compatible = "zmk,behavior-macro";
            #binding-cells = <0>;
            wait-ms = <U_ANTMORPH_MACRO_WAIT>;
            tap-ms = <U_ANTMORPH_MACRO_TAP>;
            // (t)ry {⏎
            bindings = <&macro_release &kp LCTRL>, <&macro_tap &kp R &kp Y &kp SPACE &kp LBRC &kp RET>;
        };
        amcpp_typedef: amcpp_typedef {
            compatible = "zmk,behavior-macro";
            #binding-cells = <0>;
            wait-ms = <U_ANTMORPH_MACRO_WAIT>;
            tap-ms = <U_ANTMORPH_MACRO_TAP>;
            // (t)ypedef 
            bindings = <&macro_tap &kp Y &kp P &kp E &kp D &kp E &kp F &kp SPACE>;
        };
        amcpp_sizet: amcpp_sizet {
            compatible = "zmk,behavior-macro";
            #binding-cells = <0>;
            wait-ms = <U_ANTMORPH_MACRO_WAIT>;
            tap-ms = <U_ANTMORPH_MACRO_TAP>;
            // [t]size_t
            bindings = <&macro_tap &kp BSPC &kp S &kp I &kp Z &kp E &kp UNDER &kp T>;
        };
        amcpp_ptrdifft: amcpp_ptrdifft {
            compatible = "zmk,behavior-macro";
            #binding-cells = <0>;
            wait-ms = <U_ANTMORPH_MACRO_WAIT>;
            tap-ms = <U_ANTMORPH_MACRO_TAP>;
            // [t]ptrdiff_t
            bindings = <&macro_release &kp RCTRL>, <&macro_tap &kp BSPC &kp P &kp T &kp R &kp D &kp I &kp F &kp F &kp UNDER &kp T>;
        };
        amcpp_threadlocal: amcpp_threadlocal {
            compatible = "zmk,behavior-macro";
            #binding-cells = <0>;
            wait-ms = <U_ANTMORPH_MACRO_WAIT>;
            tap-ms = <U_ANTMORPH_MACRO_TAP>;
            // (t)hread_local
            bindings = <&macro_tap &kp H &kp R &kp E &kp A &kp D &kp UNDER &kp L &kp O &kp C &kp A &kp L>;
        };
        // 'U'
        amcpp_union: amcpp_union {
            compatible = "zmk,behavior-macro";
            #binding-cells = <0>;
            wait-ms = <U_ANTMORPH_MACRO_WAIT>;
            tap-ms = <U_ANTMORPH_MACRO_TAP>;
            // (u)nion 
            bindings = <&macro_tap &kp N &kp I &kp O &kp N &kp SPACE>;
        };
        amcpp_using: amcpp_using {
            compatible = "zmk,behavior-macro";
            #binding-cells = <0>;
            wait-ms = <U_ANTMORPH_MACRO_WAIT>;
            tap-ms = <U_ANTMORPH_MACRO_TAP>;
            // (u)sing 
            bindings = <&macro_tap &kp S &kp I &kp N &kp G &kp SPACE>;
        };
        amcpp_unsigned: amcpp_unsigned {
            compatible = "zmk,behavior-macro";
            #binding-cells = <0>;
            wait-ms = <U_ANTMORPH_MACRO_WAIT>;
            tap-ms = <U_ANTMORPH_MACRO_TAP>;
            // (u)nsigned
            bindings = <&macro_tap &kp N &kp S &kp I &kp G &kp N &kp E &kp D>;
        };
        amcpp_stduniqueptr: amcpp_stduniqueptr {
            compatible = "zmk,behavior-macro";
            #binding-cells = <0>;
            wait-ms = <U_ANTMORPH_MACRO_WAIT>;
            tap-ms = <U_ANTMORPH_MACRO_TAP>;
            // [u]std::unique_ptr<
            bindings = <&macro_tap &kp BSPC &kp S &kp T &kp D &kp COLON &kp COLON &kp U &kp N &kp I &kp Q &kp U &kp E &kp UNDER &kp P &kp T &kp R &kp LT>;
        };
        amcpp_using_namespace: amcpp_using_namespace {
            compatible = "zmk,behavior-macro";
            #binding-cells = <0>;
            wait-ms = <U_ANTMORPH_MACRO_WAIT>;
            tap-ms = <U_ANTMORPH_MACRO_TAP>;
            // (u)sing namespace 
            bindings = <&macro_tap &kp S &kp I &kp N &kp G &kp SPACE &kp N &kp A &kp M &kp E &kp S &kp P &kp A &kp C &kp E &kp SPACE>;
        };
        amcpp_uint64t: amcpp_uint64t {
            compatible = "zmk,behavior-macro";
            #binding-cells = <0>;
            wait-ms = <U_ANTMORPH_MACRO_WAIT>;
            tap-ms = <U_ANTMORPH_MACRO_TAP>;
            // (u)int64_t
            bindings = <&macro_tap &kp I &kp N &kp T &kp N6 &kp N4 &kp UNDER &kp T>;
        };
        amcpp_uint32t: amcpp_uint32t {
            compatible = "zmk,behavior-macro";
            #binding-cells = <0>;
            wait-ms = <U_ANTMORPH_MACRO_WAIT>;
            tap-ms = <U_ANTMORPH_MACRO_TAP>;
            // (u)int32_t
            bindings = <&macro_release &kp RCTRL>, <&macro_tap &kp I &kp N &kp T &kp N3 &kp N2 &kp UNDER &kp T>;
        };
        amcpp_uint16t: amcpp_uint16t {
            compatible = "zmk,behavior-macro";
            #binding-cells = <0>;
            wait-ms = <U_ANTMORPH_MACRO_WAIT>;
            tap-ms = <U_ANTMORPH_MACRO_TAP>;
            // (u)int16_t
            bindings = <&macro_release &kp RALT>, <&macro_tap &kp RALT>, <&macro_tap &kp I &kp N &kp T &kp N1 &kp N6 &kp UNDER &kp T>;
        };
        amcpp_uint8t: amcpp_uint8t {
            compatible = "zmk,behavior-macro";
            #binding-cells = <0>;
            wait-ms = <U_ANTMORPH_MACRO_WAIT>;
            tap-ms = <U_ANTMORPH_MACRO_TAP>;
            // (u)int8_t
            bindings = <&macro_release &kp RGUI>, <&macro_tap &kp RGUI>, <&macro_tap &kp I &kp N &kp T &kp N8 &kp UNDER &kp T>;
        };
        // 'V'
        amcpp_stdvector: amcpp_stdvector {
            compatible = "zmk,behavior-macro";
            #binding-cells = <0>;
            wait-ms = <U_ANTMORPH_MACRO_WAIT>;
            tap-ms = <U_ANTMORPH_MACRO_TAP>;
            // [v]std::vector<
            bindings = <&macro_tap &kp BSPC &kp S &kp T &kp D &kp COLON &kp COLON &kp V &kp E &kp C &kp T &kp O &kp R &kp LT>;
        };
        amcpp_void: amcpp_void {
            compatible = "zmk,behavior-macro";
            #binding-cells = <0>;
            wait-ms = <U_ANTMORPH_MACRO_WAIT>;
            tap-ms = <U_ANTMORPH_MACRO_TAP>;
            // (v)oid
            bindings = <&macro_tap &kp O &kp I &kp D>;
        };
        amcpp_void1: amcpp_void1 {
            compatible = "zmk,behavior-macro";
            #binding-cells = <0>;
            wait-ms = <U_ANTMORPH_MACRO_WAIT>;
            tap-ms = <U_ANTMORPH_MACRO_TAP>;
            // (v)oid *
            bindings = <&macro_release &kp LCTRL>, <&macro_tap &kp O &kp I &kp D &kp SPACE &kp STAR>;
        };
        amcpp_void_const: amcpp_void_const {
            compatible = "zmk,behavior-macro";
            #binding-cells = <0>;
            wait-ms = <U_ANTMORPH_MACRO_WAIT>;
            tap-ms = <U_ANTMORPH_MACRO_TAP>;
            // (v)oid const *
            bindings = <&macro_release &kp LALT>, <&macro_tap &kp LALT>, <&macro_tap &kp O &kp I &kp D &kp SPACE &kp C &kp O &kp N &kp S &kp T &kp SPACE &kp STAR>;
        };
        amcpp_virtual: amcpp_virtual {
            compatible = "zmk,behavior-macro";
            #binding-cells = <0>;
            wait-ms = <U_ANTMORPH_MACRO_WAIT>;
            tap-ms = <U_ANTMORPH_MACRO_TAP>;
            // (v)irtual 
            bindings = <&macro_tap &kp I &kp R &kp T &kp U &kp A &kp L &kp SPACE>;
        };
        amcpp_volatile: amcpp_volatile {
            compatible = "zmk,behavior-macro";
            #binding-cells = <0>;
            wait-ms = <U_ANTMORPH_MACRO_WAIT>;
            tap-ms = <U_ANTMORPH_MACRO_TAP>;
            // (v)olatile
            bindings = <&macro_tap &kp O &kp L &kp A &kp T &kp I &kp L &kp E>;
        };
        amcpp_vprintf: amcpp_vprintf {
            compatible = "zmk,behavior-macro";
            #binding-cells = <0>;
            wait-ms = <U_ANTMORPH_MACRO_WAIT>;
            tap-ms = <U_ANTMORPH_MACRO_TAP>;
            // (v)printf(
            bindings = <&macro_tap &kp P &kp R &kp I &kp N &kp T &kp F &kp LPAR>;
        };
        amcpp_vfprintf: amcpp_vfprintf {
            compatible = "zmk,behavior-macro";
            #binding-cells = <0>;
            wait-ms = <U_ANTMORPH_MACRO_WAIT>;
            tap-ms = <U_ANTMORPH_MACRO_TAP>;
            // (v)fprintf(
            bindings = <&macro_release &kp RCTRL>, <&macro_tap &kp F &kp P &kp R &kp I &kp N &kp T &kp F &kp LPAR>;
        };
        amcpp_vsprintf: amcpp_vsprintf {
            compatible = "zmk,behavior-macro";
            #binding-cells = <0>;
            wait-ms = <U_ANTMORPH_MACRO_WAIT>;
            tap-ms = <U_ANTMORPH_MACRO_TAP>;
            // (v)sprintf(
            bindings = <&macro_release &kp RALT>, <&macro_tap &kp RALT>, <&macro_tap &kp S &kp P &kp R &kp I &kp N &kp T &kp F &kp LPAR>;
        };
        amcpp_vsnprintf: amcpp_vsnprintf {
            compatible = "zmk,behavior-macro";
            #binding-cells = <0>;
            wait-ms = <U_ANTMORPH_MACRO_WAIT>;
            tap-ms = <U_ANTMORPH_MACRO_TAP>;
            // (v)snprintf(
            bindings = <&macro_release &kp RGUI>, <&macro_tap &kp RGUI>, <&macro_tap &kp S &kp N &kp P &kp R &kp I &kp N &kp T &kp F &kp LPAR>;
        };
        // 'W'
        amcpp_while: amcpp_while {
            compatible = "zmk,behavior-macro";
            #binding-cells = <0>;
            wait-ms = <U_ANTMORPH_MACRO_WAIT>;
            tap-ms = <U_ANTMORPH_MACRO_TAP>;
            // (w)hile (
            bindings = <&macro_tap &kp H &kp I &kp L &kp E &kp SPACE &kp LPAR>;
        };
        amcpp_qwidget: amcpp_qwidget {
            compatible = "zmk,behavior-macro";
            #binding-cells = <0>;
            wait-ms = <U_ANTMORPH_MACRO_WAIT>;
            tap-ms = <U_ANTMORPH_MACRO_TAP>;
            // [w]QWidget
            bindings = <&macro_tap &kp BSPC &kp LS(Q) &kp LS(W) &kp I &kp D &kp G &kp E &kp T>;
        };
        // 'X'
        amcpp_extern: amcpp_extern {
            compatible = "zmk,behavior-macro";
            #binding-cells = <0>;
            wait-ms = <U_ANTMORPH_MACRO_WAIT>;
            tap-ms = <U_ANTMORPH_MACRO_TAP>;
            // [x]extern 
            bindings = <&macro_tap &kp BSPC &kp E &kp X &kp T &kp E &kp R &kp N &kp SPACE>;
        };
        amcpp_explicit: amcpp_explicit {
            compatible = "zmk,behavior-macro";
            #binding-cells = <0>;
            wait-ms = <U_ANTMORPH_MACRO_WAIT>;
            tap-ms = <U_ANTMORPH_MACRO_TAP>;
            // [x]explicit
            bindings = <&macro_tap &kp BSPC &kp E &kp X &kp P &kp L &kp I &kp C &kp I &kp T>;
        };
        amcpp_export: amcpp_export {
            compatible = "zmk,behavior-macro";
            #binding-cells = <0>;
            wait-ms = <U_ANTMORPH_MACRO_WAIT>;
            tap-ms = <U_ANTMORPH_MACRO_TAP>;
            // [x]export 
            bindings = <&macro_tap &kp BSPC &kp E &kp X &kp P &kp O &kp R &kp T &kp SPACE>;
        };
        amcpp_stdexchange: amcpp_stdexchange {
            compatible = "zmk,behavior-macro";
            #binding-cells = <0>;
            wait-ms = <U_ANTMORPH_MACRO_WAIT>;
            tap-ms = <U_ANTMORPH_MACRO_TAP>;
            // [x]std::exchange(
            bindings = <&macro_tap &kp BSPC &kp S &kp T &kp D &kp COLON &kp COLON &kp E &kp X &kp C &kp H &kp A &kp N &kp G &kp E &kp LPAR>;
        };
        // 'Y'
        amcpp_true: amcpp_true {
            compatible = "zmk,behavior-macro";
            #binding-cells = <0>;
            wait-ms = <U_ANTMORPH_MACRO_WAIT>;
            tap-ms = <U_ANTMORPH_MACRO_TAP>;
            // [y]true
            bindings = <&macro_tap &kp BSPC &kp T &kp R &kp U &kp E>;
        };
        // '1'
        amcpp_1024: amcpp_1024 {
            compatible = "zmk,behavior-macro";
            #binding-cells = <0>;
            wait-ms = <U_ANTMORPH_MACRO_WAIT>;
            tap-ms = <U_ANTMORPH_MACRO_TAP>;
            // (1)024
            bindings = <&macro_tap &kp N0 &kp N2 &kp N4>;
        };
        // '2'
        amcpp_stdpair: amcpp_stdpair {
            compatible = "zmk,behavior-macro";
            #binding-cells = <0>;
            wait-ms = <U_ANTMORPH_MACRO_WAIT>;
            tap-ms = <U_ANTMORPH_MACRO_TAP>;
            // [2]std::pair<
            bindings = <&macro_tap &kp BSPC &kp S &kp T &kp D &kp COLON &kp COLON &kp P &kp A &kp I &kp R &kp LT>;
        };
        // '3'
        amcpp_stdtuple: amcpp_stdtuple {
            compatible = "zmk,behavior-macro";
            #binding-cells = <0>;
            wait-ms = <U_ANTMORPH_MACRO_WAIT>;
            tap-ms = <U_ANTMORPH_MACRO_TAP>;
            // [3]std::tuple<
            bindings = <&macro_tap &kp BSPC &kp S &kp T &kp D &kp COLON &kp COLON &kp T &kp U &kp P &kp L &kp E &kp LT>;
        };
        // '4'
        amcpp_4096: amcpp_4096 {
            compatible = "zmk,behavior-macro";
            #binding-cells = <0>;
            wait-ms = <U_ANTMORPH_MACRO_WAIT>;
            tap-ms = <U_ANTMORPH_MACRO_TAP>;
            // (4)096
            bindings = <&macro_tap &kp N0 &kp N9 &kp N6>;
        };
        // ','
        amcpp_stdcout: amcpp_stdcout {
            compatible = "zmk,behavior-macro";
            #binding-cells = <0>;
            wait-ms = <U_ANTMORPH_MACRO_WAIT>;
            tap-ms = <U_ANTMORPH_MACRO_TAP>;
            // [,]std::cout
            bindings = <&macro_tap &kp BSPC &kp S &kp T &kp D &kp COLON &kp COLON &kp C &kp O &kp U &kp T>;
        };
        amcpp_m: amcpp_m {
            compatible = "zmk,behavior-macro";
            #binding-cells = <0>;
            wait-ms = <U_ANTMORPH_MACRO_WAIT>;
            tap-ms = <U_ANTMORPH_MACRO_TAP>;
            // (,) ...);
            bindings = <&macro_tap &kp SPACE &kp DOT &kp DOT &kp DOT &kp RPAR &kp SEMI>;
        };
        amcpp_m1: amcpp_m1 {
            compatible = "zmk,behavior-macro";
            #binding-cells = <0>;
            wait-ms = <U_ANTMORPH_MACRO_WAIT>;
            tap-ms = <U_ANTMORPH_MACRO_TAP>;
            // (,) ...)⏎{⏎
            bindings = <&macro_release &kp LCTRL>, <&macro_tap &kp SPACE &kp DOT &kp DOT &kp DOT &kp RPAR &kp RET &kp LBRC &kp RET>;
        };
        amcpp_m2: amcpp_m2 {
            compatible = "zmk,behavior-macro";
            #binding-cells = <0>;
            wait-ms = <U_ANTMORPH_MACRO_WAIT>;
            tap-ms = <U_ANTMORPH_MACRO_TAP>;
            // (,)=>
            bindings = <&macro_tap &kp EQUAL &kp GT>;
        };
        // '.'
        amcpp_stdcin: amcpp_stdcin {
            compatible = "zmk,behavior-macro";
            #binding-cells = <0>;
            wait-ms = <U_ANTMORPH_MACRO_WAIT>;
            tap-ms = <U_ANTMORPH_MACRO_TAP>;
            // [.]std::cin
            bindings = <&macro_tap &kp BSPC &kp S &kp T &kp D &kp COLON &kp COLON &kp C &kp I &kp N>;
        };
        amcpp_endif: amcpp_endif {
            compatible = "zmk,behavior-macro";
            #binding-cells = <0>;
            wait-ms = <U_ANTMORPH_MACRO_WAIT>;
            tap-ms = <U_ANTMORPH_MACRO_TAP>;
            // [.]#endif
            bindings = <&macro_tap &kp BSPC &kp HASH &kp E &kp N &kp D &kp I &kp F>;
        };
        // '''
        amcpp_m3: amcpp_m3 {
            compatible = "zmk,behavior-macro";
            #binding-cells = <0>;
            wait-ms = <U_ANTMORPH_MACRO_WAIT>;
            tap-ms = <U_ANTMORPH_MACRO_TAP>;
            // ('), "
            bindings = <&macro_tap &kp COMMA &kp SPACE &kp DQT>;
        };
        amcpp_m4: amcpp_m4 {
            compatible = "zmk,behavior-macro";
            #binding-cells = <0>;
            wait-ms = <U_ANTMORPH_MACRO_WAIT>;
            tap-ms = <U_ANTMORPH_MACRO_TAP>;
            // (');⏎
            bindings = <&macro_release &kp LCTRL>, <&macro_tap &kp SEMI &kp RET>;
        };
        amcpp_l1: amcpp_l1 {
            compatible = "zmk,behavior-macro";
            #binding-cells = <0>;
            wait-ms = <U_ANTMORPH_MACRO_WAIT>;
            tap-ms = <U_ANTMORPH_MACRO_TAP>;
            // (')_L1
            bindings = <&macro_release &kp LALT>, <&macro_tap &kp LALT>, <&macro_tap &kp UNDER &kp LS(L) &kp N1>;
        };
        amcpp_ba: amcpp_ba {
            compatible = "zmk,behavior-macro";
            #binding-cells = <0>;
            wait-ms = <U_ANTMORPH_MACRO_WAIT>;
            tap-ms = <U_ANTMORPH_MACRO_TAP>;
            // (')_ba
            bindings = <&macro_release &kp LGUI>, <&macro_tap &kp LGUI>, <&macro_tap &kp UNDER &kp B &kp A>;
        };
        amcpp_m5: amcpp_m5 {
            compatible = "zmk,behavior-macro";
            #binding-cells = <0>;
            wait-ms = <U_ANTMORPH_MACRO_WAIT>;
            tap-ms = <U_ANTMORPH_MACRO_TAP>;
            // ('),⏎"
            bindings = <&macro_tap &kp COMMA &kp RET &kp DQT>;
        };
        amcpp_include: amcpp_include {
            compatible = "zmk,behavior-macro";
            #binding-cells = <0>;
            wait-ms = <U_ANTMORPH_MACRO_WAIT>;
            tap-ms = <U_ANTMORPH_MACRO_TAP>;
            // [']#include ""←
            bindings = <&macro_tap &kp BSPC &kp HASH &kp I &kp N &kp C &kp L &kp U &kp D &kp E &kp SPACE &kp DQT &kp DQT &kp LEFT>;
        };
        amcpp_include_h: amcpp_include_h {
            compatible = "zmk,behavior-macro";
            #binding-cells = <0>;
            wait-ms = <U_ANTMORPH_MACRO_WAIT>;
            tap-ms = <U_ANTMORPH_MACRO_TAP>;
            // [']#include ".h"←←←
            bindings = <&macro_release &kp RCTRL>, <&macro_tap &kp BSPC &kp HASH &kp I &kp N &kp C &kp L &kp U &kp D &kp E &kp SPACE &kp DQT &kp DOT &kp H &kp DQT &kp LEFT &kp LEFT &kp LEFT>;
        };
        amcpp_include_hpp: amcpp_include_hpp {
            compatible = "zmk,behavior-macro";
            #binding-cells = <0>;
            wait-ms = <U_ANTMORPH_MACRO_WAIT>;
            tap-ms = <U_ANTMORPH_MACRO_TAP>;
            // [']#include ".hpp"←←←←←
            bindings = <&macro_release &kp RALT>, <&macro_tap &kp RALT>, <&macro_tap &kp BSPC &kp HASH &kp I &kp N &kp C &kp L &kp U &kp D &kp E &kp SPACE &kp DQT &kp DOT &kp H &kp P &kp P &kp DQT &kp LEFT &kp LEFT &kp LEFT &kp LEFT &kp LEFT>;
        };
        amcpp_include1: amcpp_include1 {
            compatible = "zmk,behavior-macro";
            #binding-cells = <0>;
            wait-ms = <U_ANTMORPH_MACRO_WAIT>;
            tap-ms = <U_ANTMORPH_MACRO_TAP>;
            // [']#include <>←
            bindings = <&macro_tap &kp BSPC &kp HASH &kp I &kp N &kp C &kp L &kp U &kp D &kp E &kp SPACE &kp LT &kp GT &kp LEFT>;
        };
        amcpp_include_h1: amcpp_include_h1 {
            compatible = "zmk,behavior-macro";
            #binding-cells = <0>;
            wait-ms = <U_ANTMORPH_MACRO_WAIT>;
            tap-ms = <U_ANTMORPH_MACRO_TAP>;
            // [']#include <.h>←←←
            bindings = <&macro_release &kp RCTRL>, <&macro_tap &kp BSPC &kp HASH &kp I &kp N &kp C &kp L &kp U &kp D &kp E &kp SPACE &kp LT &kp DOT &kp H &kp GT &kp LEFT &kp LEFT &kp LEFT>;
        };
        // '/'
        amcpp_ifdef: amcpp_ifdef {
            compatible = "zmk,behavior-macro";
            #binding-cells = <0>;
            wait-ms = <U_ANTMORPH_MACRO_WAIT>;
            tap-ms = <U_ANTMORPH_MACRO_TAP>;
            // [/]#ifdef 
            bindings = <&macro_tap &kp BSPC &kp HASH &kp I &kp F &kp D &kp E &kp F &kp SPACE>;
        };
        amcpp_ifndef: amcpp_ifndef {
            compatible = "zmk,behavior-macro";
            #binding-cells = <0>;
            wait-ms = <U_ANTMORPH_MACRO_WAIT>;
            tap-ms = <U_ANTMORPH_MACRO_TAP>;
            // [/]#ifndef 
            bindings = <&macro_release &kp RCTRL>, <&macro_tap &kp BSPC &kp HASH &kp I &kp F &kp N &kp D &kp E &kp F &kp SPACE>;
        };
        amcpp_elifdef: amcpp_elifdef {
            compatible = "zmk,behavior-macro";
            #binding-cells = <0>;
            wait-ms = <U_ANTMORPH_MACRO_WAIT>;
            tap-ms = <U_ANTMORPH_MACRO_TAP>;
            // [/]#elifdef 
            bindings = <&macro_tap &kp BSPC &kp HASH &kp E &kp L &kp I &kp F &kp D &kp E &kp F &kp SPACE>;
        };
        amcpp_elifndef: amcpp_elifndef {
            compatible = "zmk,behavior-macro";
            #binding-cells = <0>;
            wait-ms = <U_ANTMORPH_MACRO_WAIT>;
            tap-ms = <U_ANTMORPH_MACRO_TAP>;
            // [/]#elifndef 
            bindings = <&macro_release &kp RCTRL>, <&macro_tap &kp BSPC &kp HASH &kp E &kp L &kp I &kp F &kp N &kp D &kp E &kp F &kp SPACE>;
        };
        // '{'
        amcpp_m6: amcpp_m6 {
            compatible = "zmk,behavior-macro";
            #binding-cells = <0>;
            wait-ms = <U_ANTMORPH_MACRO_WAIT>;
            tap-ms = <U_ANTMORPH_MACRO_TAP>;
            // ({)},
            bindings = <&macro_tap &kp RBRC &kp COMMA>;
        };
        amcpp_m7: amcpp_m7 {
            compatible = "zmk,behavior-macro";
            #binding-cells = <0>;
            wait-ms = <U_ANTMORPH_MACRO_WAIT>;
            tap-ms = <U_ANTMORPH_MACRO_TAP>;
            // ({)};
            bindings = <&macro_tap &kp RBRC &kp SEMI>;
        };
        amcpp_m8: amcpp_m8 {
            compatible = "zmk,behavior-macro";
            #binding-cells = <0>;
            wait-ms = <U_ANTMORPH_MACRO_WAIT>;
            tap-ms = <U_ANTMORPH_MACRO_TAP>;
            // ({)};⏎
            bindings = <&macro_release &kp LCTRL>, <&macro_tap &kp RBRC &kp SEMI &kp RET>;
        };
        amcpp_m9: amcpp_m9 {
            compatible = "zmk,behavior-macro";
            #binding-cells = <0>;
            wait-ms = <U_ANTMORPH_MACRO_WAIT>;
            tap-ms = <U_ANTMORPH_MACRO_TAP>;
            // ({)}←
            bindings = <&macro_tap &kp RBRC &kp LEFT>;
        };
        // '}'
        amcpp_m10: amcpp_m10 {
            compatible = "zmk,behavior-macro";
            #binding-cells = <0>;
            wait-ms = <U_ANTMORPH_MACRO_WAIT>;
            tap-ms = <U_ANTMORPH_MACRO_TAP>;
            // (}), {
            bindings = <&macro_tap &kp COMMA &kp SPACE &kp LBRC>;
        };
        amcpp_m11: amcpp_m11 {
            compatible = "zmk,behavior-macro";
            #binding-cells = <0>;
            wait-ms = <U_ANTMORPH_MACRO_WAIT>;
            tap-ms = <U_ANTMORPH_MACRO_TAP>;
            // (});⏎
            bindings = <&macro_release &kp LCTRL>, <&macro_tap &kp SEMI &kp RET>;
        };
        amcpp_m12: amcpp_m12 {
            compatible = "zmk,behavior-macro";
            #binding-cells = <0>;
            wait-ms = <U_ANTMORPH_MACRO_WAIT>;
            tap-ms = <U_ANTMORPH_MACRO_TAP>;
            // (}),⏎{
            bindings = <&macro_tap &kp COMMA &kp RET &kp LBRC>;
        };
        // '('
        amcpp_void2: amcpp_void2 {
            compatible = "zmk,behavior-macro";
            #binding-cells = <0>;
            wait-ms = <U_ANTMORPH_MACRO_WAIT>;
            tap-ms = <U_ANTMORPH_MACRO_TAP>;
            // (()void)
            bindings = <&macro_tap &kp V &kp O &kp I &kp D &kp RPAR>;
        };
        amcpp_int_argc_char_a: amcpp_int_argc_char_a {
            compatible = "zmk,behavior-macro";
            #binding-cells = <0>;
            wait-ms = <U_ANTMORPH_MACRO_WAIT>;
            tap-ms = <U_ANTMORPH_MACRO_TAP>;
            // (()int argc, char *argv[])⏎{⏎
            bindings = <&macro_release &kp LCTRL>, <&macro_tap &kp I &kp N &kp T &kp SPACE &kp A &kp R &kp G &kp C &kp COMMA &kp SPACE &kp C &kp H &kp A &kp R &kp SPACE &kp STAR &kp A &kp R &kp G &kp V &kp LBKT &kp RBKT &kp RPAR &kp RET &kp LBRC &kp RET>;
        };
        amcpp_m13: amcpp_m13 {
            compatible = "zmk,behavior-macro";
            #binding-cells = <0>;
            wait-ms = <U_ANTMORPH_MACRO_WAIT>;
            tap-ms = <U_ANTMORPH_MACRO_TAP>;
            // (());
            bindings = <&macro_tap &kp RPAR &kp SEMI>;
        };
        amcpp_m14: amcpp_m14 {
            compatible = "zmk,behavior-macro";
            #binding-cells = <0>;
            wait-ms = <U_ANTMORPH_MACRO_WAIT>;
            tap-ms = <U_ANTMORPH_MACRO_TAP>;
            // (());⏎
            bindings = <&macro_release &kp LCTRL>, <&macro_tap &kp RPAR &kp SEMI &kp RET>;
        };
        amcpp_m15: amcpp_m15 {
            compatible = "zmk,behavior-macro";
            #binding-cells = <0>;
            wait-ms = <U_ANTMORPH_MACRO_WAIT>;
            tap-ms = <U_ANTMORPH_MACRO_TAP>;
            // (())←
            bindings = <&macro_tap &kp RPAR &kp LEFT>;
        };
        // ')'
        amcpp_m16: amcpp_m16 {
            compatible = "zmk,behavior-macro";
            #binding-cells = <0>;
            wait-ms = <U_ANTMORPH_MACRO_WAIT>;
            tap-ms = <U_ANTMORPH_MACRO_TAP>;
            // ()) {⏎
            bindings = <&macro_tap &kp SPACE &kp LBRC &kp RET>;
        };
        amcpp_m17: amcpp_m17 {
            compatible = "zmk,behavior-macro";
            #binding-cells = <0>;
            wait-ms = <U_ANTMORPH_MACRO_WAIT>;
            tap-ms = <U_ANTMORPH_MACRO_TAP>;
            // ());⏎
            bindings = <&macro_release &kp LCTRL>, <&macro_tap &kp SEMI &kp RET>;
        };
        amcpp_m18: amcpp_m18 {
            compatible = "zmk,behavior-macro";
            #binding-cells = <0>;
            wait-ms = <U_ANTMORPH_MACRO_WAIT>;
            tap-ms = <U_ANTMORPH_MACRO_TAP>;
            // ())⏎{⏎
            bindings = <&macro_tap &kp RET &kp LBRC &kp RET>;
        };
        amcpp_m19: amcpp_m19 {
            compatible = "zmk,behavior-macro";
            #binding-cells = <0>;
            wait-ms = <U_ANTMORPH_MACRO_WAIT>;
            tap-ms = <U_ANTMORPH_MACRO_TAP>;
            // ())⏎: 
            bindings = <&macro_tap &kp RET &kp COLON &kp SPACE>;
        };
        // '*'
        amcpp_void3: amcpp_void3 {
            compatible = "zmk,behavior-macro";
            #binding-cells = <0>;
            wait-ms = <U_ANTMORPH_MACRO_WAIT>;
            tap-ms = <U_ANTMORPH_MACRO_TAP>;
            // [*]void *
            bindings = <&macro_tap &kp BSPC &kp V &kp O &kp I &kp D &kp SPACE &kp STAR>;
        };
        amcpp_void_const1: amcpp_void_const1 {
            compatible = "zmk,behavior-macro";
            #binding-cells = <0>;
            wait-ms = <U_ANTMORPH_MACRO_WAIT>;
            tap-ms = <U_ANTMORPH_MACRO_TAP>;
            // [*]void const *
            bindings = <&macro_release &kp LCTRL>, <&macro_tap &kp BSPC &kp V &kp O &kp I &kp D &kp SPACE &kp C &kp O &kp N &kp S &kp T &kp SPACE &kp STAR>;
        };
        amcpp_char2: amcpp_char2 {
            compatible = "zmk,behavior-macro";
            #binding-cells = <0>;
            wait-ms = <U_ANTMORPH_MACRO_WAIT>;
            tap-ms = <U_ANTMORPH_MACRO_TAP>;
            // [*]char *
            bindings = <&macro_tap &kp BSPC &kp C &kp H &kp A &kp R &kp SPACE &kp STAR>;
        };
        amcpp_char_const1: amcpp_char_const1 {
            compatible = "zmk,behavior-macro";
            #binding-cells = <0>;
            wait-ms = <U_ANTMORPH_MACRO_WAIT>;
            tap-ms = <U_ANTMORPH_MACRO_TAP>;
            // [*]char const *
            bindings = <&macro_release &kp LCTRL>, <&macro_tap &kp BSPC &kp C &kp H &kp A &kp R &kp SPACE &kp C &kp O &kp N &kp S &kp T &kp SPACE &kp STAR>;
        };
        // ':'
        amcpp_qt: amcpp_qt {
            compatible = "zmk,behavior-macro";
            #binding-cells = <0>;
            wait-ms = <U_ANTMORPH_MACRO_WAIT>;
            tap-ms = <U_ANTMORPH_MACRO_TAP>;
            // [:]Qt::
            bindings = <&macro_tap &kp BSPC &kp LS(Q) &kp T &kp COLON &kp COLON>;
        };
        amcpp_std: amcpp_std {
            compatible = "zmk,behavior-macro";
            #binding-cells = <0>;
            wait-ms = <U_ANTMORPH_MACRO_WAIT>;
            tap-ms = <U_ANTMORPH_MACRO_TAP>;
            // [:]std::
            bindings = <&macro_tap &kp BSPC &kp S &kp T &kp D &kp COLON &kp COLON>;
        };
        amcpp_boost: amcpp_boost {
            compatible = "zmk,behavior-macro";
            #binding-cells = <0>;
            wait-ms = <U_ANTMORPH_MACRO_WAIT>;
            tap-ms = <U_ANTMORPH_MACRO_TAP>;
            // [:]boost::
            bindings = <&macro_tap &kp BSPC &kp B &kp O &kp O &kp S &kp T &kp COLON &kp COLON>;
        };
        // '+'
        amcpp_05: amcpp_05 {
            compatible = "zmk,behavior-macro";
            #binding-cells = <0>;
            wait-ms = <U_ANTMORPH_MACRO_WAIT>;
            tap-ms = <U_ANTMORPH_MACRO_TAP>;
            // (+) 0.5
            bindings = <&macro_tap &kp SPACE &kp N0 &kp DOT &kp N5>;
        };
        // '!'
        amcpp_defined1: amcpp_defined1 {
            compatible = "zmk,behavior-macro";
            #binding-cells = <0>;
            wait-ms = <U_ANTMORPH_MACRO_WAIT>;
            tap-ms = <U_ANTMORPH_MACRO_TAP>;
            // (!)defined(
            bindings = <&macro_tap &kp D &kp E &kp F &kp I &kp N &kp E &kp D &kp LPAR>;
        };
        // '#'
        amcpp_error: amcpp_error {
            compatible = "zmk,behavior-macro";
            #binding-cells = <0>;
            wait-ms = <U_ANTMORPH_MACRO_WAIT>;
            tap-ms = <U_ANTMORPH_MACRO_TAP>;
            // (#)error 
            bindings = <&macro_tap &kp E &kp R &kp R &kp O &kp R &kp SPACE>;
        };
        amcpp_pragma: amcpp_pragma {
            compatible = "zmk,behavior-macro";
            #binding-cells = <0>;
            wait-ms = <U_ANTMORPH_MACRO_WAIT>;
            tap-ms = <U_ANTMORPH_MACRO_TAP>;
            // (#)pragma 
            bindings = <&macro_tap &kp P &kp R &kp A &kp G &kp M &kp A &kp SPACE>;
        };
        amcpp_pragma_once: amcpp_pragma_once {
            compatible = "zmk,behavior-macro";
            #binding-cells = <0>;
            wait-ms = <U_ANTMORPH_MACRO_WAIT>;
            tap-ms = <U_ANTMORPH_MACRO_TAP>;
            // (#)pragma once
            bindings = <&macro_release &kp LCTRL>, <&macro_tap &kp P &kp R &kp A &kp G &kp M &kp A &kp SPACE &kp O &kp N &kp C &kp E>;
        };
        amcpp_warning: amcpp_warning {
            compatible = "zmk,behavior-macro";
            #binding-cells = <0>;
            wait-ms = <U_ANTMORPH_MACRO_WAIT>;
            tap-ms = <U_ANTMORPH_MACRO_TAP>;
            // (#)warning 
            bindings = <&macro_tap &kp W &kp A &kp R &kp N &kp I &kp N &kp G &kp SPACE>;
        };
        amcpp_embed: amcpp_embed {
            compatible = "zmk,behavior-macro";
            #binding-cells = <0>;
            wait-ms = <U_ANTMORPH_MACRO_WAIT>;
            tap-ms = <U_ANTMORPH_MACRO_TAP>;
            // (#)embed 
            bindings = <&macro_tap &kp E &kp M &kp B &kp E &kp D &kp SPACE>;
        };
        // '_'
        amcpp_l11: amcpp_l11 {
            compatible = "zmk,behavior-macro";
            #binding-cells = <0>;
            wait-ms = <U_ANTMORPH_MACRO_WAIT>;
            tap-ms = <U_ANTMORPH_MACRO_TAP>;
            // (_)L1
            bindings = <&macro_tap &kp LS(L) &kp N1>;
        };
        amcpp_thread: amcpp_thread {
            compatible = "zmk,behavior-macro";
            #binding-cells = <0>;
            wait-ms = <U_ANTMORPH_MACRO_WAIT>;
            tap-ms = <U_ANTMORPH_MACRO_TAP>;
            // (_)_thread
            bindings = <&macro_tap &kp UNDER &kp T &kp H &kp R &kp E &kp A &kp D>;
        };
        amcpp_attribute: amcpp_attribute {
            compatible = "zmk,behavior-macro";
            #binding-cells = <0>;
            wait-ms = <U_ANTMORPH_MACRO_WAIT>;
            tap-ms = <U_ANTMORPH_MACRO_TAP>;
            // (_)_attribute__ ((
            bindings = <&macro_tap &kp UNDER &kp A &kp T &kp T &kp R &kp I &kp B &kp U &kp T &kp E &kp UNDER &kp UNDER &kp SPACE &kp LPAR &kp LPAR>;
        };
        amcpp_attribute_visib: amcpp_attribute_visib {
            compatible = "zmk,behavior-macro";
            #binding-cells = <0>;
            wait-ms = <U_ANTMORPH_MACRO_WAIT>;
            tap-ms = <U_ANTMORPH_MACRO_TAP>;
            // (_)_attribute__ ((visibility ("hidden")))
            bindings = <&macro_release &kp RCTRL>, <&macro_tap &kp UNDER &kp A &kp T &kp T &kp R &kp I &kp B &kp U &kp T &kp E &kp UNDER &kp UNDER &kp SPACE &kp LPAR &kp LPAR &kp V &kp I &kp S &kp I &kp B &kp I &kp L &kp I &kp T &kp Y &kp SPACE &kp LPAR &kp DQT &kp H &kp I &kp D &kp D &kp E &kp N &kp DQT &kp RPAR &kp RPAR &kp RPAR>;
        };
        amcpp_attribute_visib1: amcpp_attribute_visib1 {
            compatible = "zmk,behavior-macro";
            #binding-cells = <0>;
            wait-ms = <U_ANTMORPH_MACRO_WAIT>;
            tap-ms = <U_ANTMORPH_MACRO_TAP>;
            // (_)_attribute__ ((visibility ("default")))
            bindings = <&macro_release &kp RALT>, <&macro_tap &kp RALT>, <&macro_tap &kp UNDER &kp A &kp T &kp T &kp R &kp I &kp B &kp U &kp T &kp E &kp UNDER &kp UNDER &kp SPACE &kp LPAR &kp LPAR &kp V &kp I &kp S &kp I &kp B &kp I &kp L &kp I &kp T &kp Y &kp SPACE &kp LPAR &kp DQT &kp D &kp E &kp F &kp A &kp U &kp L &kp T &kp DQT &kp RPAR &kp RPAR &kp RPAR>;
        };
        amcpp_attribute_secti: amcpp_attribute_secti {
            compatible = "zmk,behavior-macro";
            #binding-cells = <0>;
            wait-ms = <U_ANTMORPH_MACRO_WAIT>;
            tap-ms = <U_ANTMORPH_MACRO_TAP>;
            // (_)_attribute__ ((section("")))←←←←
            bindings = <&macro_release &kp RGUI>, <&macro_tap &kp RGUI>, <&macro_tap &kp UNDER &kp A &kp T &kp T &kp R &kp I &kp B &kp U &kp T &kp E &kp UNDER &kp UNDER &kp SPACE &kp LPAR &kp LPAR &kp S &kp E &kp C &kp T &kp I &kp O &kp N &kp LPAR &kp DQT &kp DQT &kp RPAR &kp RPAR &kp RPAR &kp LEFT &kp LEFT &kp LEFT &kp LEFT>;
        };
        amcpp_declspec: amcpp_declspec {
            compatible = "zmk,behavior-macro";
            #binding-cells = <0>;
            wait-ms = <U_ANTMORPH_MACRO_WAIT>;
            tap-ms = <U_ANTMORPH_MACRO_TAP>;
            // (_)_declspec(
            bindings = <&macro_tap &kp UNDER &kp D &kp E &kp C &kp L &kp S &kp P &kp E &kp C &kp LPAR>;
        };
        // '['
        amcpp_m20: amcpp_m20 {
            compatible = "zmk,behavior-macro";
            #binding-cells = <0>;
            wait-ms = <U_ANTMORPH_MACRO_WAIT>;
            tap-ms = <U_ANTMORPH_MACRO_TAP>;
            // ([)=]
            bindings = <&macro_tap &kp EQUAL &kp RBKT>;
        };
        amcpp_this1: amcpp_this1 {
            compatible = "zmk,behavior-macro";
            #binding-cells = <0>;
            wait-ms = <U_ANTMORPH_MACRO_WAIT>;
            tap-ms = <U_ANTMORPH_MACRO_TAP>;
            // ([)this]
            bindings = <&macro_release &kp LCTRL>, <&macro_tap &kp T &kp H &kp I &kp S &kp RBKT>;
        };
        amcpp_m21: amcpp_m21 {
            compatible = "zmk,behavior-macro";
            #binding-cells = <0>;
            wait-ms = <U_ANTMORPH_MACRO_WAIT>;
            tap-ms = <U_ANTMORPH_MACRO_TAP>;
            // ([)&]
            bindings = <&macro_release &kp LALT>, <&macro_tap &kp LALT>, <&macro_tap &kp AMPS &kp RBKT>;
        };
        amcpp_m22: amcpp_m22 {
            compatible = "zmk,behavior-macro";
            #binding-cells = <0>;
            wait-ms = <U_ANTMORPH_MACRO_WAIT>;
            tap-ms = <U_ANTMORPH_MACRO_TAP>;
            // ([)];
            bindings = <&macro_tap &kp RBKT &kp SEMI>;
        };
        amcpp_m23: amcpp_m23 {
            compatible = "zmk,behavior-macro";
            #binding-cells = <0>;
            wait-ms = <U_ANTMORPH_MACRO_WAIT>;
            tap-ms = <U_ANTMORPH_MACRO_TAP>;
            // ([)];⏎
            bindings = <&macro_release &kp LCTRL>, <&macro_tap &kp RBKT &kp SEMI &kp RET>;
        };
        amcpp_m24: amcpp_m24 {
            compatible = "zmk,behavior-macro";
            #binding-cells = <0>;
            wait-ms = <U_ANTMORPH_MACRO_WAIT>;
            tap-ms = <U_ANTMORPH_MACRO_TAP>;
            // ([)[]]←←
            bindings = <&macro_tap &kp LBKT &kp RBKT &kp RBKT &kp LEFT &kp LEFT>;
        };
        amcpp_deprecated: amcpp_deprecated {
            compatible = "zmk,behavior-macro";
            #binding-cells = <0>;
            wait-ms = <U_ANTMORPH_MACRO_WAIT>;
            tap-ms = <U_ANTMORPH_MACRO_TAP>;
            // ([)[deprecated]]
            bindings = <&macro_release &kp LCTRL>, <&macro_tap &kp LBKT &kp D &kp E &kp P &kp R &kp E &kp C &kp A &kp T &kp E &kp D &kp RBKT &kp RBKT>;
        };
        amcpp_deprecated1: amcpp_deprecated1 {
            compatible = "zmk,behavior-macro";
            #binding-cells = <0>;
            wait-ms = <U_ANTMORPH_MACRO_WAIT>;
            tap-ms = <U_ANTMORPH_MACRO_TAP>;
            // ([)[deprecated()]]←←←
            bindings = <&macro_release &kp LALT>, <&macro_tap &kp LALT>, <&macro_tap &kp LBKT &kp D &kp E &kp P &kp R &kp E &kp C &kp A &kp T &kp E &kp D &kp LPAR &kp RPAR &kp RBKT &kp RBKT &kp LEFT &kp LEFT &kp LEFT>;
        };
        amcpp_expects: amcpp_expects {
            compatible = "zmk,behavior-macro";
            #binding-cells = <0>;
            wait-ms = <U_ANTMORPH_MACRO_WAIT>;
            tap-ms = <U_ANTMORPH_MACRO_TAP>;
            // ([)[expects:]]←←
            bindings = <&macro_tap &kp LBKT &kp E &kp X &kp P &kp E &kp C &kp T &kp S &kp COLON &kp RBKT &kp RBKT &kp LEFT &kp LEFT>;
        };
        amcpp_fallthrough: amcpp_fallthrough {
            compatible = "zmk,behavior-macro";
            #binding-cells = <0>;
            wait-ms = <U_ANTMORPH_MACRO_WAIT>;
            tap-ms = <U_ANTMORPH_MACRO_TAP>;
            // ([)[fallthrough]];
            bindings = <&macro_tap &kp LBKT &kp F &kp A &kp L &kp L &kp T &kp H &kp R &kp O &kp U &kp G &kp H &kp RBKT &kp RBKT &kp SEMI>;
        };
        amcpp_likely: amcpp_likely {
            compatible = "zmk,behavior-macro";
            #binding-cells = <0>;
            wait-ms = <U_ANTMORPH_MACRO_WAIT>;
            tap-ms = <U_ANTMORPH_MACRO_TAP>;
            // ([)[likely]]
            bindings = <&macro_release &kp RCTRL>, <&macro_tap &kp LBKT &kp L &kp I &kp K &kp E &kp L &kp Y &kp RBKT &kp RBKT>;
        };
        amcpp_unlikely: amcpp_unlikely {
            compatible = "zmk,behavior-macro";
            #binding-cells = <0>;
            wait-ms = <U_ANTMORPH_MACRO_WAIT>;
            tap-ms = <U_ANTMORPH_MACRO_TAP>;
            // ([)[unlikely]]
            bindings = <&macro_release &kp RALT>, <&macro_tap &kp RALT>, <&macro_tap &kp LBKT &kp U &kp N &kp L &kp I &kp K &kp E &kp L &kp Y &kp RBKT &kp RBKT>;
        };
        amcpp_maybeunused: amcpp_maybeunused {
            compatible = "zmk,behavior-macro";
            #binding-cells = <0>;
            wait-ms = <U_ANTMORPH_MACRO_WAIT>;
            tap-ms = <U_ANTMORPH_MACRO_TAP>;
            // ([)[maybe_unused]]
            bindings = <&macro_tap &kp LBKT &kp M &kp A &kp Y &kp B &kp E &kp UNDER &kp U &kp N &kp U &kp S &kp E &kp D &kp RBKT &kp RBKT>;
        };
        amcpp_nodiscard: amcpp_nodiscard {
            compatible = "zmk,behavior-macro";
            #binding-cells = <0>;
            wait-ms = <U_ANTMORPH_MACRO_WAIT>;
            tap-ms = <U_ANTMORPH_MACRO_TAP>;
            // ([)[nodiscard]]
            bindings = <&macro_release &kp RCTRL>, <&macro_tap &kp LBKT &kp N &kp O &kp D &kp I &kp S &kp C &kp A &kp R &kp D &kp RBKT &kp RBKT>;
        };
        amcpp_nodiscard1: amcpp_nodiscard1 {
            compatible = "zmk,behavior-macro";
            #binding-cells = <0>;
            wait-ms = <U_ANTMORPH_MACRO_WAIT>;
            tap-ms = <U_ANTMORPH_MACRO_TAP>;
            // ([)[nodiscard()]]←←←
            bindings = <&macro_release &kp RALT>, <&macro_tap &kp RALT>, <&macro_tap &kp LBKT &kp N &kp O &kp D &kp I &kp S &kp C &kp A &kp R &kp D &kp LPAR &kp RPAR &kp RBKT &kp RBKT &kp LEFT &kp LEFT &kp LEFT>;
        };
        // ']'
        amcpp_m25: amcpp_m25 {
            compatible = "zmk,behavior-macro";
            #binding-cells = <0>;
            wait-ms = <U_ANTMORPH_MACRO_WAIT>;
            tap-ms = <U_ANTMORPH_MACRO_TAP>;
            // (]) = 
            bindings = <&macro_tap &kp SPACE &kp EQUAL &kp SPACE>;
        };
        amcpp_m26: amcpp_m26 {
            compatible = "zmk,behavior-macro";
            #binding-cells = <0>;
            wait-ms = <U_ANTMORPH_MACRO_WAIT>;
            tap-ms = <U_ANTMORPH_MACRO_TAP>;
            // (]) = {
            bindings = <&macro_release &kp LCTRL>, <&macro_tap &kp SPACE &kp EQUAL &kp SPACE &kp LBRC>;
        };
        amcpp_m27: amcpp_m27 {
            compatible = "zmk,behavior-macro";
            #binding-cells = <0>;
            wait-ms = <U_ANTMORPH_MACRO_WAIT>;
            tap-ms = <U_ANTMORPH_MACRO_TAP>;
            // (]);⏎
            bindings = <&macro_release &kp LCTRL>, <&macro_tap &kp SEMI &kp RET>;
        };
        // ';'
        amcpp_m28: amcpp_m28 {
            compatible = "zmk,behavior-macro";
            #binding-cells = <0>;
            wait-ms = <U_ANTMORPH_MACRO_WAIT>;
            tap-ms = <U_ANTMORPH_MACRO_TAP>;
            // (;)⏎}
            bindings = <&macro_tap &kp RET &kp RBRC>;
        };
        amcpp_m29: amcpp_m29 {
            compatible = "zmk,behavior-macro";
            #binding-cells = <0>;
            wait-ms = <U_ANTMORPH_MACRO_WAIT>;
            tap-ms = <U_ANTMORPH_MACRO_TAP>;
            // (;)⏎}⏎⏎
            bindings = <&macro_tap &kp RET &kp RBRC &kp RET &kp RET>;
        };
        // '='
        amcpp_m30: amcpp_m30 {
            compatible = "zmk,behavior-macro";
            #binding-cells = <0>;
            wait-ms = <U_ANTMORPH_MACRO_WAIT>;
            tap-ms = <U_ANTMORPH_MACRO_TAP>;
            // (=) {
            bindings = <&macro_tap &kp SPACE &kp LBRC>;
        };
        amcpp_m31: amcpp_m31 {
            compatible = "zmk,behavior-macro";
            #binding-cells = <0>;
            wait-ms = <U_ANTMORPH_MACRO_WAIT>;
            tap-ms = <U_ANTMORPH_MACRO_TAP>;
            // (=) {"
            bindings = <&macro_release &kp LCTRL>, <&macro_tap &kp SPACE &kp LBRC &kp DQT>;
        };
        amcpp_m32: amcpp_m32 {
            compatible = "zmk,behavior-macro";
            #binding-cells = <0>;
            wait-ms = <U_ANTMORPH_MACRO_WAIT>;
            tap-ms = <U_ANTMORPH_MACRO_TAP>;
            // (=) {'
            bindings = <&macro_release &kp LALT>, <&macro_tap &kp LALT>, <&macro_tap &kp SPACE &kp LBRC &kp APOS>;
        };
        amcpp_01: amcpp_01 {
            compatible = "zmk,behavior-macro";
            #binding-cells = <0>;
            wait-ms = <U_ANTMORPH_MACRO_WAIT>;
            tap-ms = <U_ANTMORPH_MACRO_TAP>;
            // (=) 0;
            bindings = <&macro_tap &kp SPACE &kp N0 &kp SEMI>;
        };
        amcpp_00: amcpp_00 {
            compatible = "zmk,behavior-macro";
            #binding-cells = <0>;
            wait-ms = <U_ANTMORPH_MACRO_WAIT>;
            tap-ms = <U_ANTMORPH_MACRO_TAP>;
            // (=) 0.0;
            bindings = <&macro_release &kp LCTRL>, <&macro_tap &kp SPACE &kp N0 &kp DOT &kp N0 &kp SEMI>;
        };
        amcpp_m33: amcpp_m33 {
            compatible = "zmk,behavior-macro";
            #binding-cells = <0>;
            wait-ms = <U_ANTMORPH_MACRO_WAIT>;
            tap-ms = <U_ANTMORPH_MACRO_TAP>;
            // (=) {};
            bindings = <&macro_tap &kp SPACE &kp LBRC &kp RBRC &kp SEMI>;
        };
        amcpp_02: amcpp_02 {
            compatible = "zmk,behavior-macro";
            #binding-cells = <0>;
            wait-ms = <U_ANTMORPH_MACRO_WAIT>;
            tap-ms = <U_ANTMORPH_MACRO_TAP>;
            // (=) {0};
            bindings = <&macro_release &kp LCTRL>, <&macro_tap &kp SPACE &kp LBRC &kp N0 &kp RBRC &kp SEMI>;
        };
        // '\'
        amcpp_rn: amcpp_rn {
            compatible = "zmk,behavior-macro";
            #binding-cells = <0>;
            wait-ms = <U_ANTMORPH_MACRO_WAIT>;
            tap-ms = <U_ANTMORPH_MACRO_TAP>;
            // (\)r\n
            bindings = <&macro_tap &kp R &kp BSLH &kp N>;
        };
        amcpp_rnrn: amcpp_rnrn {
            compatible = "zmk,behavior-macro";
            #binding-cells = <0>;
            wait-ms = <U_ANTMORPH_MACRO_WAIT>;
            tap-ms = <U_ANTMORPH_MACRO_TAP>;
            // (\)r\n\r\n
            bindings = <&macro_tap &kp R &kp BSLH &kp N &kp BSLH &kp R &kp BSLH &kp N>;
        };
        // ' '
        amcpp_cpp_v29: amcpp_cpp_v29 {
            compatible = "zmk,behavior-macro";
            #binding-cells = <0>;
            wait-ms = <U_ANTMORPH_MACRO_WAIT>;
            tap-ms = <U_ANTMORPH_MACRO_TAP>;
            // [ ]Cpp v2.9
            bindings = <&macro_tap &kp BSPC &kp LS(C) &kp P &kp P &kp SPACE &kp V &kp N2 &kp DOT &kp N9>;
        };
        amcpp_undef: amcpp_undef {
            compatible = "zmk,behavior-macro";
            #binding-cells = <0>;
            wait-ms = <U_ANTMORPH_MACRO_WAIT>;
            tap-ms = <U_ANTMORPH_MACRO_TAP>;
            // [ ]#undef 
            bindings = <&macro_tap &kp BSPC &kp HASH &kp U &kp N &kp D &kp E &kp F &kp SPACE>;
        };
    };
};
